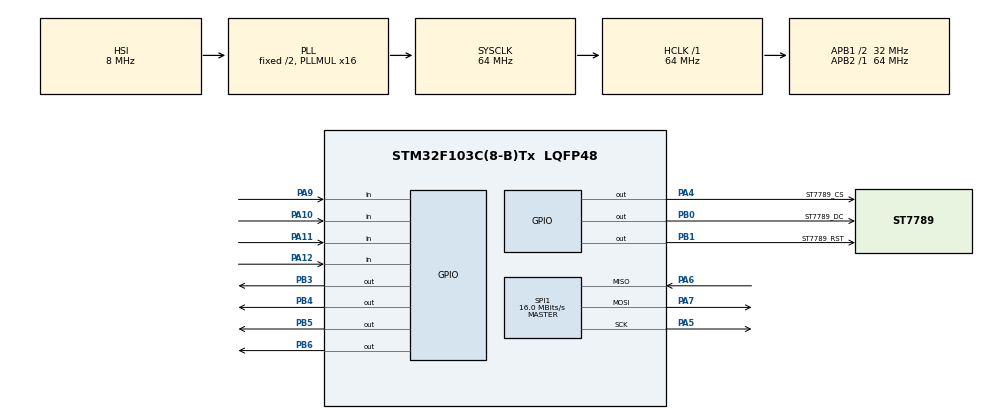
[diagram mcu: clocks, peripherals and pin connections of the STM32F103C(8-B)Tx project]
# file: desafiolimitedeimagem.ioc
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Mcu.Family=STM32F1
Mcu.Name=STM32F103C(8-B)Tx
Mcu.Package=LQFP48
NVIC.PriorityGroup=NVIC_PRIORITYGROUP_4
PA10.Signal=GPIO_Input
PA11.Signal=GPIO_Input
PA12.Signal=GPIO_Input
PA13.Mode=Serial_Wire
PA13.Signal=SYS_JTMS-SWDIO
PA14.Mode=Serial_Wire
PA14.Signal=SYS_JTCK-SWCLK
PA4.GPIO_Label=ST7789_CS
PA4.Signal=GPIO_Output
PA5.Mode=Full_Duplex_Master
PA5.Signal=SPI1_SCK
PA6.Mode=Full_Duplex_Master
PA6.Signal=SPI1_MISO
PA7.Mode=Full_Duplex_Master
PA7.Signal=SPI1_MOSI
PA9.Signal=GPIO_Input
PB0.GPIO_Label=ST7789_DC
PB0.Signal=GPIO_Output
PB1.GPIO_Label=ST7789_RST
PB1.Signal=GPIO_Output
PB3.Signal=GPIO_Output
PB4.Signal=GPIO_Output
PB5.Signal=GPIO_Output
PB6.Signal=GPIO_Output
ProjectManager.HeapSize=0x200
ProjectManager.StackSize=0x400
ProjectManager.TargetToolchain=STM32CubeIDE
RCC.AHBFreq_Value=64000000
RCC.APB1CLKDivider=RCC_HCLK_DIV2
RCC.APB1Freq_Value=32000000
RCC.APB1TimFreq_Value=64000000
RCC.APB2Freq_Value=64000000
RCC.APB2TimFreq_Value=64000000
RCC.HCLKFreq_Value=64000000
RCC.PLLMUL=RCC_PLL_MUL16
RCC.SYSCLKFreq_VALUE=64000000
RCC.SYSCLKSource=RCC_SYSCLKSOURCE_PLLCLK
RCC.USBFreq_Value=64000000
SPI1.BaudRatePrescaler=SPI_BAUDRATEPRESCALER_4
SPI1.CLKPolarity=SPI_POLARITY_HIGH
SPI1.CalculateBaudRate=16.0 MBits/s
SPI1.Direction=SPI_DIRECTION_2LINES
SPI1.Mode=SPI_MODE_MASTER
SPI1.VirtualType=VM_MASTER
board=custom

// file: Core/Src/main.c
/* USER CODE BEGIN Header */
/**
  ******************************************************************************
  * @file           : main.c
  * @brief          : Main program body
  ******************************************************************************
  * @attention
  *
  * <h2><center>&copy; Copyright (c) 2025 STMicroelectronics.
  * All rights reserved.</center></h2>
  *
  * This software component is licensed by ST under BSD 3-Clause license,
  * the "License"; You may not use this file except in compliance with the
  * License. You may obtain a copy of the License at:
  *                        opensource.org/licenses/BSD-3-Clause
  *
  ******************************************************************************
  */
/* USER CODE END Header */
#include "main.h"
#include "ST7789\ST7789.h"

SPI_HandleTypeDef hspi1;

/* USER CODE BEGIN PV */

#define IMG0_HEIGHT 60
#define IMG0_WIDTH 60

// array size is 7200
static const uint16_t img0[][60*60/2]  = {
  0xffff, 0xffff, 0xffff, 0xffff, 0xffff, 0xffff, 0xffff, 0xffff, 0xffff, 0xffff, 0xffff, 0xffff, 0xffff, 0xffff, 0xffff, 0xffff, 0xffff, 0xffff, 0xffff, 0xffff, 0xffff, 0xffff, 0xffff, 0xffff, 0xffff, 0xffff, 0xffff, 0xffff, 0xffff, 0xffff, 0xffff, 0xffff, 0xffff, 0xffff, 0xffff, 0xffff, 0xffff, 0xffff, 0xffff, 0xffff, 0xffff, 0xffff, 0xffff, 0xffff, 0xffff, 0xffff, 0xffff, 0xffff, 0xffff, 0xffff, 0xffff, 0xffff, 0xffff, 0xffff, 0xffff, 0xffff, 0xffff, 0xffff, 0xffff, 0xffff,
  0xffff, 0xffff, 0xffff, 0xffff, 0xffff, 0xffff, 0xffff, 0xffff, 0xffff, 0xffff, 0xffff, 0xffff, 0xffff, 0xffff, 0xffff, 0xffff, 0xffff, 0xffff, 0xffff, 0xffff, 0xffff, 0xffff, 0xffff, 0xffff, 0xffff, 0xffff, 0xffff, 0xffff, 0xffff, 0xffff, 0xffff, 0xffff, 0xffff, 0xffff, 0xffff, 0xffff, 0xffff, 0xffff, 0xffff, 0xffff, 0xffff, 0xffff, 0xffff, 0xffff, 0xffff, 0xffff, 0xffff, 0xffff, 0xffff, 0xffff, 0xffff, 0xffff, 0xffff, 0xffff, 0xffff, 0xffff, 0xffff, 0xffff, 0xffff, 0xffff,
  0xffff, 0xffff, 0xffff, 0xffff, 0xffff, 0xffff, 0xffff, 0xffff, 0xffff, 0xffff, 0xffff, 0xffff, 0xffff, 0xffff, 0xffff, 0xffff, 0xffff, 0xffff, 0xffff, 0xffff, 0xffff, 0xffff, 0xffff, 0xffff, 0xffff, 0xffff, 0xffff, 0xffff, 0xffff, 0xffff, 0xffff, 0xffff, 0xffff, 0xffff, 0xffff, 0xffff, 0xffff, 0xffff, 0xffff, 0xffff, 0xffff, 0xffff, 0xffff, 0xffff, 0xffff, 0xffff, 0xffff, 0xffff, 0xffff, 0xffff, 0xffff, 0xffff, 0xffff, 0xffff, 0xffff, 0xffff, 0xffff, 0xffff, 0xffff, 0xffff,
  0xffff, 0xffff, 0xffff, 0xffff, 0xffff, 0xffff, 0xffff, 0xffff, 0xffff, 0xffff, 0xffff, 0xffff, 0xffff, 0xffff, 0xffff, 0xffff, 0xffff, 0xffff, 0xffff, 0xffff, 0xffff, 0xffff, 0xffff, 0xffff, 0xffff, 0xffff, 0xffff, 0xffff, 0xffff, 0xffff, 0xffff, 0xffff, 0xffff, 0xffff, 0xffff, 0xffff, 0xffff, 0xffff, 0xffff, 0xffff, 0xffff, 0xffff, 0xffff, 0xffff, 0xffff, 0xffff, 0xffff, 0xffff, 0xffff, 0xffff, 0xffff, 0xffff, 0xffff, 0xffff, 0xffff, 0xffff, 0xffff, 0xffff, 0xffff, 0xffff,
  0xffff, 0xffff, 0xffff, 0xffff, 0xffff, 0xffff, 0xffff, 0xffff, 0xffff, 0xffff, 0xffff, 0xffff, 0xffff, 0xffff, 0xffff, 0xffff, 0xffff, 0xffff, 0xffff, 0xffff, 0xffff, 0xffff, 0xffff, 0xffff, 0xffff, 0xffff, 0xffff, 0xffff, 0xffff, 0xffff, 0xffff, 0xffff, 0xffff, 0xffff, 0xffff, 0xffff, 0xffff, 0xffff, 0xffff, 0xffff, 0xffff, 0xffff, 0xffff, 0xffff, 0xffff, 0xffff, 0xffff, 0xffff, 0xffff, 0xffff, 0xffff, 0xffff, 0xffff, 0xffff, 0xffff, 0xffff, 0xffff, 0xffff, 0xffff, 0xffff,
  0xffff, 0xffff, 0xffff, 0xffff, 0xffff, 0xffff, 0xffff, 0xffff, 0xffff, 0xffff, 0xffff, 0xffff, 0xffff, 0xffff, 0xffff, 0xffff, 0xffff, 0xffff, 0xffff, 0xffff, 0xffff, 0xffff, 0xffff, 0xffff, 0xffff, 0xffff, 0xffff, 0xffff, 0xffff, 0xffff, 0xffff, 0xffff, 0xffff, 0xffff, 0xffff, 0xffff, 0xffff, 0xffff, 0xffff, 0xffff, 0xffff, 0xffff, 0xffff, 0xffff, 0xffff, 0xffff, 0xffff, 0xffff, 0xffff, 0xffff, 0xffff, 0xffff, 0xffff, 0xffff, 0xffff, 0xffff, 0xffff, 0xffff, 0xffff, 0xffff,
  0xffff, 0xffff, 0xffff, 0xffff, 0xffff, 0xffff, 0xffff, 0xffff, 0xffff, 0xffff, 0xffff, 0xffff, 0xffff, 0xffff, 0xffff, 0xffff, 0xffff, 0xffff, 0xffff, 0xffff, 0xffff, 0xffff, 0xffff, 0xffff, 0xffff, 0xffff, 0xffff, 0xffff, 0xffff, 0xffff, 0xffff, 0xffff, 0xffff, 0xffff, 0xffff, 0xffff, 0xffff, 0xffff, 0xffff, 0xffff, 0xffff, 0xffff, 0xffff, 0xffff, 0xffff, 0xffff, 0xffff, 0xffff, 0xffff, 0xffff, 0xffff, 0xffff, 0xffff, 0xffff, 0xffff, 0xffff, 0xffff, 0xffff, 0xffff, 0xffff,
  0xffff, 0xffff, 0xffff, 0xffff, 0xffff, 0xffff, 0xffff, 0xffff, 0xffff, 0xffff, 0xffff, 0xffff, 0xffff, 0xffff, 0xffff, 0xffff, 0xffff, 0xffff, 0xffff, 0xffff, 0xffff, 0xffff, 0xffff, 0xffff, 0xffff, 0xffff, 0xffff, 0xffff, 0xffff, 0xffff, 0xffff, 0xffff, 0xffff, 0xffff, 0xffff, 0xffff, 0xffff, 0xffff, 0xffff, 0xffff, 0xffff, 0xffff, 0xffff, 0xffff, 0xffff, 0xffff, 0xffff, 0xffff, 0xffff, 0xffff, 0xffff, 0xffff, 0xffff, 0xffff, 0xffff, 0xffff, 0xffff, 0xffff, 0xffff, 0xffff,
  0xffff, 0xffff, 0xffff, 0xffff, 0xffff, 0xffff, 0xffff, 0xffff, 0xffff, 0xffff, 0xffff, 0xffff, 0xffff, 0xffff, 0xffff, 0xffff, 0xffff, 0xffff, 0xffff, 0xffff, 0xffff, 0xffff, 0xffff, 0xffff, 0xffff, 0xffff, 0xffff, 0xffff, 0xffff, 0xffff, 0xffff, 0xffff, 0xffff, 0xffff, 0xffff, 0xffff, 0xffff, 0xffff, 0xffff, 0xffff, 0xffff, 0xffff, 0xffff, 0xffff, 0xffff, 0xffff, 0xffff, 0xffff, 0xffff, 0xffff, 0xffff, 0xffff, 0xffff, 0xffff, 0xffff, 0xffff, 0xffff, 0xffff, 0xffff, 0xffff,
  0xffff, 0xffff, 0xffff, 0xffff, 0xffff, 0xffff, 0xffff, 0xffff, 0xffff, 0xffff, 0xffff, 0xffff, 0xffff, 0xffff, 0xffff, 0xffff, 0xffff, 0xffff, 0xffff, 0xffff, 0xffff, 0xffff, 0xffff, 0xffff, 0xffff, 0xffff, 0xffff, 0xffff, 0xffff, 0xffff, 0xffff, 0xffff, 0xffff, 0xffff, 0xffff, 0xffff, 0xffff, 0xffff, 0xffff, 0xffff, 0xffff, 0xffff, 0xffff, 0xffff, 0xffff, 0xffff, 0xffff, 0xffff, 0xffff, 0xffff, 0xffff, 0xffff, 0xffff, 0xffff, 0xffff, 0xffff, 0xffff, 0xffff, 0xffff, 0xffff,
  0xffff, 0xffff, 0xffff, 0xffff, 0xffff, 0xffff, 0xffff, 0xffff, 0xffff, 0xffff, 0xffff, 0xffff, 0xffff, 0xffff, 0xffff, 0xffff, 0xffff, 0xffff, 0xffff, 0xffff, 0xffff, 0xffff, 0xffff, 0xffff, 0xffff, 0xffff, 0xffff, 0xffff, 0xffff, 0xffff, 0xffff, 0xffff, 0xffff, 0xffff, 0xffff, 0xffff, 0xffff, 0xffff, 0xffff, 0xffff, 0xffff, 0xffff, 0xffff, 0xffff, 0xffff, 0xffff, 0xffff, 0xffff, 0xffff, 0xffff, 0xffff, 0xffff, 0xffff, 0xffff, 0xffff, 0xffff, 0xffff, 0xffff, 0xffff, 0xffff,
  0xffff, 0xffff, 0xffff, 0xffff, 0xffff, 0xffff, 0xffff, 0xffff, 0xffff, 0xffff, 0xffff, 0xffff, 0xffff, 0xffff, 0xffff, 0xffff, 0xffff, 0xffff, 0xffff, 0xffff, 0xffff, 0xffff, 0xffff, 0xffff, 0xffff, 0xffff, 0xffff, 0xffff, 0xffff, 0xffff, 0xffff, 0xffff, 0xffff, 0xffff, 0xffff, 0xffff, 0xffff, 0xffff, 0xffff, 0xffff, 0xffff, 0xffff, 0xffff, 0xffff, 0xffff, 0xffff, 0xffff, 0xffff, 0xffff, 0xffff, 0xffff, 0xffff, 0xffff, 0xffff, 0xffff, 0xffff, 0xffff, 0xffff, 0xffff, 0xffff,
  0xffff, 0xffff, 0xffff, 0xffff, 0xffff, 0xffff, 0xffff, 0xffff, 0xffff, 0xffff, 0xffff, 0xffff, 0xffff, 0xffff, 0xffff, 0xffff, 0xffff, 0xffff, 0xffff, 0xffff, 0xffff, 0xffff, 0xffff, 0xffff, 0xffff, 0xffff, 0xffff, 0xffff, 0xffff, 0xffff, 0xffff, 0xffff, 0xffff, 0xffff, 0xffff, 0xffff, 0xffff, 0xffff, 0xffff, 0xffff, 0xffff, 0xffff, 0xffff, 0xffff, 0xffff, 0xffff, 0xffff, 0xffff, 0xffff, 0xffff, 0xffff, 0xffff, 0xffff, 0xffff, 0xffff, 0xffff, 0xffff, 0xffff, 0xffff, 0xffff,
  0xffff, 0xffff, 0xffff, 0xffff, 0xffff, 0xffff, 0xffff, 0xffff, 0xffff, 0xffff, 0xffff, 0xffff, 0xffff, 0xffff, 0xffff, 0xffff, 0xffff, 0xffff, 0xffff, 0xffff, 0xffff, 0xffff, 0xffff, 0xffff, 0xffff, 0xffff, 0xffff, 0xffff, 0xffff, 0xffff, 0xffff, 0xffff, 0xffff, 0xffff, 0xffff, 0xffff, 0xffff, 0xffff, 0xffff, 0xffff, 0xffff, 0xffff, 0xffff, 0xffff, 0xffff, 0xffff, 0xffff, 0xffff, 0xffff, 0xffff, 0xffff, 0xffff, 0xffff, 0xffff, 0xffff, 0xffff, 0xffff, 0xffff, 0xffff, 0xffff,
  0xffff, 0xffff, 0xffff, 0xffff, 0xffff, 0xffff, 0xffff, 0xffff, 0xffff, 0xffff, 0xffff, 0xffff, 0xffff, 0xffff, 0xffff, 0xffff, 0xffff, 0xffff, 0xffff, 0xffff, 0xffff, 0xffff, 0xffff, 0xffff, 0xffff, 0xffff, 0xffff, 0xffff, 0xffff, 0xffff, 0xffff, 0xffff, 0xffff, 0xffff, 0xffff, 0xffff, 0xffff, 0xffff, 0xffff, 0xffff, 0xffff, 0xffff, 0xffff, 0xffff, 0xffff, 0xffff, 0xffff, 0xffff, 0xffff, 0xffff, 0xffff, 0xffff, 0xffff, 0xffff, 0xffff, 0xffff, 0xffff, 0xffff, 0xffff, 0xffff,
  0xffff, 0xffff, 0xffff, 0xffff, 0xffff, 0xffff, 0xffff, 0xffff, 0xffff, 0xffff, 0xffff, 0xffff, 0xffff, 0xffff, 0xffff, 0xffff, 0xffff, 0xffff, 0xffff, 0xffff, 0xffff, 0xffff, 0xffff, 0xffff, 0xffff, 0xffff, 0xffff, 0xffff, 0xffff, 0xffff, 0xffff, 0xffff, 0xffff, 0xffff, 0xffff, 0xffff, 0xffff, 0xffff, 0xffff, 0xffff, 0xffff, 0xffff, 0xffff, 0xffff, 0xffff, 0xffff, 0xffff, 0xffff, 0xffff, 0xffff, 0xffff, 0xffff, 0xffff, 0xffff, 0xffff, 0xffff, 0xffff, 0xffff, 0xffff, 0xffff,
  0xffff, 0xffff, 0xffff, 0xffff, 0xffff, 0xffff, 0xffff, 0xffff, 0xffff, 0xffff, 0xffff, 0xffff, 0xffff, 0xffff, 0xffff, 0xffff, 0xffff, 0xffff, 0xffff, 0xffff, 0xffff, 0xffff, 0xffff, 0xffff, 0xffff, 0xffff, 0xdef7, 0xbdef, 0x7bd7, 0x5ac7, 0x59c7, 0x59c7, 0x59c7, 0x7bcf, 0xbde7, 0xdeef, 0xfff7, 0xffff, 0xffff, 0xffff, 0xffff, 0xffff, 0xffff, 0xffff, 0xffff, 0xffff, 0xffff, 0xffff, 0xffff, 0xffff, 0xffff, 0xffff, 0xffff, 0xffff, 0xffff, 0xffff, 0xffff, 0xffff, 0xffff, 0xffff,
  0xffff, 0xffff, 0xffff, 0xffff, 0xffff, 0xffff, 0xffff, 0xffff, 0xffff, 0xffff, 0xffff, 0xffff, 0xffff, 0xffff, 0xffff, 0xffff, 0xffff, 0xffff, 0xffff, 0xffff, 0xffff, 0xffff, 0xffff, 0xffff, 0xffff, 0xffff, 0xbce7, 0x59bf, 0x7176, 0xed4d, 0xed4d, 0xed4d, 0xed4d, 0x516e, 0x17af, 0x7acf, 0xbde7, 0xdef7, 0xffff, 0xffff, 0xffff, 0xffff, 0xffff, 0xffff, 0xffff, 0xffff, 0xffff, 0xffff, 0xffff, 0xffff, 0xffff, 0xffff, 0xffff, 0xffff, 0xffff, 0xffff, 0xffff, 0xffff, 0xffff, 0xffff,
  0xffff, 0xffff, 0xffff, 0xffff, 0xffff, 0xffff, 0xffff, 0xffff, 0xffff, 0xffff, 0xffff, 0xffff, 0xffff, 0xffff, 0xffff, 0xffff, 0xffff, 0xffff, 0xffff, 0xffff, 0xffff, 0xffff, 0xffff, 0xffff, 0xdef7, 0xbde7, 0x38b7, 0x9386, 0xed45, 0x8925, 0x8925, 0x8925, 0x8925, 0xcc3d, 0x7176, 0xd59e, 0x5ac7, 0xbde7, 0xffff, 0xffff, 0xffff, 0xffff, 0xffff, 0xffff, 0xffff, 0xffff, 0xffff, 0xffff, 0xffff, 0xffff, 0xffff, 0xffff, 0xffff, 0xffff, 0xffff, 0xffff, 0xffff, 0xffff, 0xffff, 0xffff,
  0xffff, 0xffff, 0xffff, 0xffff, 0xffff, 0xffff, 0xffff, 0xffff, 0xffff, 0xffff, 0xffff, 0xffff, 0xffff, 0xffff, 0xffff, 0xffff, 0xffff, 0xffff, 0xffff, 0xffff, 0xffff, 0xffff, 0xffff, 0xffff, 0xbce7, 0x59c7, 0x516e, 0xab35, 0x8a2d, 0x8925, 0x8925, 0x8925, 0x8925, 0x8a25, 0xaa35, 0x2f5e, 0xd59e, 0x7bcf, 0xffff, 0xffff, 0xffff, 0xffff, 0xffff, 0xffff, 0xffff, 0xffff, 0xffff, 0xffff, 0xffff, 0xffff, 0xffff, 0xffff, 0xffff, 0xffff, 0xffff, 0xffff, 0xffff, 0xffff, 0xffff, 0xffff,
  0xffff, 0xffff, 0xffff, 0xffff, 0xffff, 0xffff, 0xffff, 0xffff, 0xffff, 0xffff, 0xffff, 0xffff, 0xffff, 0xffff, 0xffff, 0xffff, 0xffff, 0xffff, 0xffff, 0xffff, 0xffff, 0xffff, 0xffff, 0xffff, 0x39bf, 0x9386, 0xed45, 0x8925, 0x8925, 0x8925, 0x8925, 0x8925, 0x8925, 0x8925, 0x8925, 0xcc3d, 0x5066, 0x38b7, 0xffff, 0xffff, 0xffff, 0xffff, 0xffff, 0xffff, 0xffff, 0xffff, 0xffff, 0xffff, 0xffff, 0xffff, 0xffff, 0xffff, 0xffff, 0xffff, 0xffff, 0xffff, 0xffff, 0xffff, 0xffff, 0xffff,
  0xffff, 0xffff, 0xffff, 0xffff, 0xffff, 0xffff, 0xffff, 0xffff, 0xffff, 0xffff, 0xffff, 0xffff, 0xffff, 0xffff, 0xffff, 0xffff, 0xffff, 0xffff, 0xffff, 0xffff, 0xffff, 0xffff, 0xffff, 0xffff, 0xb386, 0xaa2d, 0x8925, 0x8925, 0x8925, 0x8925, 0x8925, 0x8925, 0x8925, 0x8925, 0x8925, 0x8925, 0x8a2d, 0xd596, 0xffff, 0xffff, 0xffff, 0xffff, 0xffff, 0xffff, 0xffff, 0xffff, 0xffff, 0xffff, 0xffff, 0xffff, 0xffff, 0xffff, 0xffff, 0xffff, 0xffff, 0xffff, 0xffff, 0xffff, 0xffff, 0xffff,
  0xffff, 0xffff, 0xffff, 0xffff, 0xffff, 0xffff, 0xffff, 0xffff, 0xffff, 0xffff, 0xffff, 0xffff, 0xffff, 0xffff, 0xffff, 0xffff, 0xffff, 0xffff, 0xffff, 0xffff, 0xffff, 0xffff, 0xffff, 0xffff, 0x9386, 0x8925, 0x8925, 0x8925, 0x8925, 0x8925, 0x8925, 0x8925, 0x8925, 0x8925, 0x8925, 0x8925, 0x8925, 0xd496, 0xffff, 0xffff, 0xffff, 0xffff, 0xffff, 0xffff, 0xffff, 0xffff, 0xffff, 0xffff, 0xffff, 0xffff, 0xffff, 0xffff, 0xffff, 0xffff, 0xffff, 0xffff, 0xffff, 0xffff, 0xffff, 0xffff,
  0xffff, 0xffff, 0xffff, 0xffff, 0xffff, 0xffff, 0xffff, 0xffff, 0xffff, 0xffff, 0xffff, 0xffff, 0xffff, 0xffff, 0xffff, 0xffff, 0xffff, 0xffff, 0xffff, 0xffff, 0xffff, 0xffff, 0xffff, 0xffff, 0x937e, 0x8925, 0x8925, 0x8925, 0x8925, 0x8925, 0x8925, 0x8925, 0x8925, 0x8925, 0x8925, 0x8925, 0x8925, 0xd496, 0xffff, 0xffff, 0xffff, 0xffff, 0xffff, 0xffff, 0xffff, 0xffff, 0xffff, 0xffff, 0xffff, 0xffff, 0xffff, 0xffff, 0xffff, 0xffff, 0xffff, 0xffff, 0xffff, 0xffff, 0xffff, 0xffff,
  0xffff, 0xffff, 0xffff, 0xffff, 0xffff, 0xffff, 0xffff, 0xffff, 0xffff, 0xffff, 0xffff, 0xffff, 0xffff, 0xffff, 0xffff, 0xffff, 0xffff, 0xffff, 0xffff, 0xffff, 0xffff, 0xffff, 0xffff, 0xffff, 0x9386, 0x8925, 0x8925, 0x8925, 0x8925, 0x8925, 0x8925, 0x8925, 0x8925, 0x8925, 0x8925, 0x8925, 0x8925, 0xd496, 0xffff, 0xffff, 0xffff, 0xffff, 0xffff, 0xffff, 0xffff, 0xffff, 0xffff, 0xffff, 0xffff, 0xffff, 0xffff, 0xffff, 0xffff, 0xffff, 0xffff, 0xffff, 0xffff, 0xffff, 0xffff, 0xffff,
  0xffff, 0xffff, 0xffff, 0xffff, 0xffff, 0xffff, 0xffff, 0xffff, 0xffff, 0xffff, 0xffff, 0xffff, 0xffff, 0xffff, 0xffff, 0xffff, 0xffff, 0xffff, 0xffff, 0xffff, 0xffff, 0xffff, 0xffff, 0xffff, 0x9386, 0x8a2d, 0x8925, 0x8925, 0x8925, 0x8925, 0x8925, 0x8925, 0x8925, 0x8925, 0x8925, 0x8925, 0x8925, 0xd496, 0xffff, 0xffff, 0xffff, 0xffff, 0xffff, 0xffff, 0xffff, 0xffff, 0xffff, 0xffff, 0xffff, 0xffff, 0xffff, 0xffff, 0xffff, 0xffff, 0xffff, 0xffff, 0xffff, 0xffff, 0xffff, 0xffff,
  0xffff, 0xffff, 0xffff, 0xffff, 0xffff, 0xffff, 0xffff, 0xffff, 0xffff, 0xffff, 0xffff, 0xffff, 0xffff, 0xffff, 0xffff, 0xffff, 0xffff, 0xffff, 0xffff, 0xffff, 0xffff, 0xffff, 0xffff, 0xffff, 0x17b7, 0x516e, 0xcc45, 0x8925, 0x8925, 0x8925, 0x8925, 0x8925, 0x8925, 0x8925, 0x8925, 0x8925, 0x8925, 0xd496, 0xffff, 0xffff, 0xffff, 0xffff, 0xffff, 0xffff, 0xffff, 0xffff, 0xffff, 0xffff, 0xffff, 0xffff, 0xffff, 0xffff, 0xffff, 0xffff, 0xffff, 0xffff, 0xffff, 0xffff, 0xffff, 0xffff,
  0xffff, 0xffff, 0xffff, 0xffff, 0xffff, 0xffff, 0xffff, 0xffff, 0xffff, 0xffff, 0xffff, 0xffff, 0xffff, 0xffff, 0xffff, 0xffff, 0xffff, 0xffff, 0xffff, 0xffff, 0xffff, 0xffff, 0xffff, 0xffff, 0x7bd7, 0xf6a6, 0x2f5e, 0xaa2d, 0x8925, 0x8925, 0x8925, 0x8925, 0x8925, 0x8925, 0x8925, 0x8a2d, 0xab35, 0xd59e, 0xffff, 0xffff, 0xffff, 0xffff, 0xffff, 0xffff, 0xffff, 0xffff, 0xffff, 0xffff, 0xffff, 0xffff, 0xffff, 0xffff, 0xffff, 0xffff, 0xffff, 0xffff, 0xffff, 0xffff, 0xffff, 0xffff,
  0xffff, 0xffff, 0xffff, 0xffff, 0xffff, 0xffff, 0xffff, 0xffff, 0xffff, 0xffff, 0xffff, 0xffff, 0xffff, 0xffff, 0xffff, 0xffff, 0xffff, 0xffff, 0xffff, 0xffff, 0xffff, 0xffff, 0xffff, 0xffff, 0xbde7, 0x7acf, 0xd596, 0x506e, 0xcc3d, 0x8925, 0x8925, 0x8925, 0x8925, 0x8925, 0x8925, 0xed4d, 0x9386, 0x5ac7, 0xffff, 0xffff, 0xffff, 0xffff, 0xffff, 0xffff, 0xffff, 0xffff, 0xffff, 0xffff, 0xffff, 0xffff, 0xffff, 0xffff, 0xffff, 0xffff, 0xffff, 0xffff, 0xffff, 0xffff, 0xffff, 0xffff,
  0xffff, 0xffff, 0xffff, 0xffff, 0xffff, 0xffff, 0xffff, 0xffff, 0xffff, 0xffff, 0xffff, 0xffff, 0xffff, 0xffff, 0xffff, 0xffff, 0xffff, 0xffff, 0xffff, 0xffff, 0xffff, 0xffff, 0xffff, 0xffff, 0xdef7, 0xbde7, 0x59c7, 0xf69e, 0x506e, 0xed4d, 0xed4d, 0xed4d, 0xed4d, 0xed4d, 0xed4d, 0x927e, 0x59c7, 0xbde7, 0xffff, 0xffff, 0xffff, 0xffff, 0xffff, 0xffff, 0xffff, 0xffff, 0xffff, 0xffff, 0xffff, 0xffff, 0xffff, 0xffff, 0xffff, 0xffff, 0xffff, 0xffff, 0xffff, 0xffff, 0xffff, 0xffff,
  0xffff, 0xffff, 0xffff, 0xffff, 0xffff, 0xffff, 0xffff, 0xffff, 0xffff, 0xffff, 0xffff, 0xffff, 0xffff, 0xffff, 0xffff, 0xffff, 0xffff, 0xffff, 0xffff, 0xffff, 0xffff, 0xffff, 0xffff, 0xffff, 0xffff, 0xfff7, 0xddef, 0xbce7, 0x7bd7, 0x5ac7, 0x5ac7, 0x5ac7, 0x5ac7, 0x5ac7, 0x5ac7, 0x9bd7, 0xddef, 0xfff7, 0xffff, 0xffff, 0xffff, 0xffff, 0xffff, 0xffff, 0xffff, 0xffff, 0xffff, 0xffff, 0xffff, 0xffff, 0xffff, 0xffff, 0xffff, 0xffff, 0xffff, 0xffff, 0xffff, 0xffff, 0xffff, 0xffff,
  0xffff, 0xffff, 0xffff, 0xffff, 0xffff, 0xffff, 0xffff, 0xffff, 0xffff, 0xffff, 0xffff, 0xffff, 0xffff, 0xffff, 0xffff, 0xffff, 0xffff, 0xffff, 0xffff, 0xffff, 0xffff, 0xffff, 0xffff, 0xffff, 0xffff, 0xffff, 0xffff, 0xffff, 0xffff, 0xffff, 0xffff, 0xffff, 0xffff, 0xffff, 0xffff, 0xffff, 0xffff, 0xffff, 0xffff, 0xffff, 0xffff, 0xffff, 0xffff, 0xffff, 0xffff, 0xffff, 0xffff, 0xffff, 0xffff, 0xffff, 0xffff, 0xffff, 0xffff, 0xffff, 0xffff, 0xffff, 0xffff, 0xffff, 0xffff, 0xffff,
  0xffff, 0xffff, 0xffff, 0xffff, 0xffff, 0xffff, 0xffff, 0xffff, 0xffff, 0xffff, 0xffff, 0xffff, 0xffff, 0xffff, 0xffff, 0xffff, 0xffff, 0xffff, 0xffff, 0xffff, 0xffff, 0xffff, 0xffff, 0xffff, 0xffff, 0xffff, 0xffff, 0xffff, 0xffff, 0xffff, 0xffff, 0xffff, 0xffff, 0xffff, 0xffff, 0xffff, 0xffff, 0xffff, 0xffff, 0xffff, 0xffff, 0xffff, 0xffff, 0xffff, 0xffff, 0xffff, 0xffff, 0xffff, 0xffff, 0xffff, 0xffff, 0xffff, 0xffff, 0xffff, 0xffff, 0xffff, 0xffff, 0xffff, 0xffff, 0xffff,
  0xffff, 0xffff, 0xffff, 0xffff, 0xffff, 0xffff, 0xffff, 0xffff, 0xffff, 0xffff, 0xffff, 0xffff, 0xffff, 0xffff, 0xffff, 0xffff, 0xffff, 0xffff, 0xffff, 0xffff, 0xffff, 0xffff, 0xffff, 0xffff, 0xffff, 0xffff, 0xffff, 0xffff, 0xffff, 0xffff, 0xffff, 0xffff, 0xffff, 0xffff, 0xffff, 0xffff, 0xffff, 0xffff, 0xffff, 0xffff, 0xffff, 0xffff, 0xffff, 0xffff, 0xffff, 0xffff, 0xffff, 0xffff, 0xffff, 0xffff, 0xffff, 0xffff, 0xffff, 0xffff, 0xffff, 0xffff, 0xffff, 0xffff, 0xffff, 0xffff,
  0xffff, 0xffff, 0xffff, 0xffff, 0xffff, 0xffff, 0xffff, 0xffff, 0xffff, 0xffff, 0xffff, 0xffff, 0xffff, 0xffff, 0xffff, 0xffff, 0xffff, 0xffff, 0xffff, 0xffff, 0xffff, 0xffff, 0xffff, 0xffff, 0xffff, 0xffff, 0xffff, 0xffff, 0xffff, 0xffff, 0xffff, 0xffff, 0xffff, 0xffff, 0xffff, 0xffff, 0xffff, 0xffff, 0xffff, 0xffff, 0xffff, 0xffff, 0xffff, 0xffff, 0xffff, 0xffff, 0xffff, 0xffff, 0xffff, 0xffff, 0xffff, 0xffff, 0xffff, 0xffff, 0xffff, 0xffff, 0xffff, 0xffff, 0xffff, 0xffff,
  0xffff, 0xffff, 0xffff, 0xffff, 0xffff, 0xffff, 0xffff, 0xffff, 0xffff, 0xffff, 0xffff, 0xffff, 0xffff, 0xffff, 0xffff, 0xffff, 0xffff, 0xffff, 0xffff, 0xffff, 0xffff, 0xffff, 0xffff, 0xffff, 0xffff, 0xffff, 0xffff, 0xffff, 0xffff, 0xffff, 0xffff, 0xffff, 0xffff, 0xffff, 0xffff, 0xffff, 0xffff, 0xffff, 0xffff, 0xffff, 0xffff, 0xffff, 0xffff, 0xffff, 0xffff, 0xffff, 0xffff, 0xffff, 0xffff, 0xffff, 0xffff, 0xffff, 0xffff, 0xffff, 0xffff, 0xffff, 0xffff, 0xffff, 0xffff, 0xffff,
  0xffff, 0xffff, 0xffff, 0xffff, 0xffff, 0xffff, 0xffff, 0xffff, 0xffff, 0xffff, 0xffff, 0xffff, 0xffff, 0xffff, 0xffff, 0xffff, 0xffff, 0xffff, 0xffff, 0xffff, 0xffff, 0xffff, 0xffff, 0xffff, 0xffff, 0xffff, 0xffff, 0xffff, 0xffff, 0xffff, 0xffff, 0xffff, 0xffff, 0xffff, 0xffff, 0xffff, 0xffff, 0xffff, 0xffff, 0xffff, 0xffff, 0xffff, 0xffff, 0xffff, 0xffff, 0xffff, 0xffff, 0xffff, 0xffff, 0xffff, 0xffff, 0xffff, 0xffff, 0xffff, 0xffff, 0xffff, 0xffff, 0xffff, 0xffff, 0xffff,
  0xffff, 0xffff, 0xffff, 0xffff, 0xffff, 0xffff, 0xffff, 0xffff, 0xffff, 0xffff, 0xffff, 0xffff, 0xffff, 0xffff, 0xffff, 0xffff, 0xffff, 0xffff, 0xffff, 0xffff, 0xffff, 0xffff, 0xffff, 0xffff, 0xffff, 0xffff, 0xffff, 0xffff, 0xffff, 0xffff, 0xffff, 0xffff, 0xffff, 0xffff, 0xffff, 0xffff, 0xffff, 0xffff, 0xffff, 0xffff, 0xffff, 0xffff, 0xffff, 0xffff, 0xffff, 0xffff, 0xffff, 0xffff, 0xffff, 0xffff, 0xffff, 0xffff, 0xffff, 0xffff, 0xffff, 0xffff, 0xffff, 0xffff, 0xffff, 0xffff,
  0xffff, 0xffff, 0xffff, 0xffff, 0xffff, 0xffff, 0xffff, 0xffff, 0xffff, 0xffff, 0xffff, 0xffff, 0xffff, 0xffff, 0xffff, 0xffff, 0xffff, 0xffff, 0xffff, 0xffff, 0xffff, 0xffff, 0xffff, 0xffff, 0xffff, 0xffff, 0xffff, 0xffff, 0xffff, 0xffff, 0xffff, 0xffff, 0xffff, 0xffff, 0xffff, 0xffff, 0xffff, 0xffff, 0xffff, 0xffff, 0xffff, 0xffff, 0xffff, 0xffff, 0xffff, 0xffff, 0xffff, 0xffff, 0xffff, 0xffff, 0xffff, 0xffff, 0xffff, 0xffff, 0xffff, 0xffff, 0xffff, 0xffff, 0xffff, 0xffff,
  0xffff, 0xffff, 0xffff, 0xffff, 0xffff, 0xffff, 0xffff, 0xffff, 0xffff, 0xffff, 0xffff, 0xffff, 0xffff, 0xffff, 0xffff, 0xffff, 0xffff, 0xffff, 0xffff, 0xffff, 0xffff, 0xffff, 0xffff, 0xffff, 0xffff, 0xffff, 0xffff, 0xffff, 0xffff, 0xffff, 0xffff, 0xffff, 0xffff, 0xffff, 0xffff, 0xffff, 0xffff, 0xffff, 0xffff, 0xffff, 0xffff, 0xffff, 0xffff, 0xffff, 0xffff, 0xffff, 0xffff, 0xffff, 0xffff, 0xffff, 0xffff, 0xffff, 0xffff, 0xffff, 0xffff, 0xffff, 0xffff, 0xffff, 0xffff, 0xffff,
  0xffff, 0xffff, 0xffff, 0xffff, 0xffff, 0xffff, 0xffff, 0xffff, 0xffff, 0xffff, 0xffff, 0xffff, 0xffff, 0xffff, 0xffff, 0xffff, 0xffff, 0xffff, 0xffff, 0xffff, 0xffff, 0xffff, 0xffff, 0xffff, 0xffff, 0xffff, 0xffff, 0xffff, 0xffff, 0xffff, 0xffff, 0xffff, 0xffff, 0xffff, 0xffff, 0xffff, 0xffff, 0xffff, 0xffff, 0xffff, 0xffff, 0xffff, 0xffff, 0xffff, 0xffff, 0xffff, 0xffff, 0xffff, 0xffff, 0xffff, 0xffff, 0xffff, 0xffff, 0xffff, 0xffff, 0xffff, 0xffff, 0xffff, 0xffff, 0xffff,
  0xffff, 0xffff, 0xffff, 0xffff, 0xffff, 0xffff, 0xffff, 0xffff, 0xffff, 0xffff, 0xffff, 0xffff, 0xffff, 0xffff, 0xffff, 0xffff, 0xffff, 0xffff, 0xffff, 0xffff, 0xffff, 0xffff, 0xffff, 0xffff, 0xffff, 0xffff, 0xffff, 0xffff, 0xffff, 0xffff, 0xffff, 0xffff, 0xffff, 0xffff, 0xffff, 0xffff, 0xffff, 0xffff, 0xffff, 0xffff, 0xffff, 0xffff, 0xffff, 0xffff, 0xffff, 0xffff, 0xffff, 0xffff, 0xffff, 0xffff, 0xffff, 0xffff, 0xffff, 0xffff, 0xffff, 0xffff, 0xffff, 0xffff, 0xffff, 0xffff,
  0xffff, 0xffff, 0xffff, 0xffff, 0xffff, 0xffff, 0xffff, 0xffff, 0xffff, 0xffff, 0xffff, 0xffff, 0xffff, 0xffff, 0xffff, 0xffff, 0xffff, 0xffff, 0xffff, 0xffff, 0xffff, 0xffff, 0xffff, 0xffff, 0xffff, 0xffff, 0xffff, 0xffff, 0xffff, 0xffff, 0xffff, 0xffff, 0xffff, 0xffff, 0xffff, 0xffff, 0xffff, 0xffff, 0xffff, 0xffff, 0xffff, 0xffff, 0xffff, 0xffff, 0xffff, 0xffff, 0xffff, 0xffff, 0xffff, 0xffff, 0xffff, 0xffff, 0xffff, 0xffff, 0xffff, 0xffff, 0xffff, 0xffff, 0xffff, 0xffff,
  0xffff, 0xffff, 0xffff, 0xffff, 0xffff, 0xffff, 0xffff, 0xffff, 0xffff, 0xffff, 0xffff, 0xffff, 0xffff, 0xffff, 0xffff, 0xffff, 0xffff, 0xffff, 0xffff, 0xffff, 0xffff, 0xffff, 0xffff, 0xffff, 0xffff, 0xffff, 0xffff, 0xffff, 0xffff, 0xffff, 0xffff, 0xffff, 0xffff, 0xffff, 0xffff, 0xffff, 0xffff, 0xffff, 0xffff, 0xffff, 0xffff, 0xffff, 0xffff, 0xffff, 0xffff, 0xffff, 0xffff, 0xffff, 0xffff, 0xffff, 0xffff, 0xffff, 0xffff, 0xffff, 0xffff, 0xffff, 0xffff, 0xffff, 0xffff, 0xffff,
  0xffff, 0xffff, 0xffff, 0xffff, 0xffff, 0xffff, 0xffff, 0xffff, 0xffff, 0xffff, 0xffff, 0xffff, 0xffff, 0xffff, 0xffff, 0xffff, 0xffff, 0xffff, 0xffff, 0xffff, 0xffff, 0xffff, 0xffff, 0xffff, 0xffff, 0xffff, 0xffff, 0xffff, 0xffff, 0xffff, 0xffff, 0xffff, 0xffff, 0xffff, 0xffff, 0xffff, 0xffff, 0xffff, 0xffff, 0xffff, 0xffff, 0xffff, 0xffff, 0xffff, 0xffff, 0xffff, 0xffff, 0xffff, 0xffff, 0xffff, 0xffff, 0xffff, 0xffff, 0xffff, 0xffff, 0xffff, 0xffff, 0xffff, 0xffff, 0xffff,
  0xffff, 0xffff, 0xffff, 0xffff, 0xffff, 0xffff, 0xffff, 0xffff, 0xffff, 0xffff, 0xffff, 0xffff, 0xffff, 0xffff, 0xffff, 0xffff, 0xffff, 0xffff, 0xffff, 0xffff, 0xffff, 0xffff, 0xffff, 0xffff, 0xffff, 0xffff, 0xffff, 0xffff, 0xffff, 0xffff, 0xffff, 0xffff, 0xffff, 0xffff, 0xffff, 0xffff, 0xffff, 0xffff, 0xffff, 0xffff, 0xffff, 0xffff, 0xffff, 0xffff, 0xffff, 0xffff, 0xffff, 0xffff, 0xffff, 0xffff, 0xffff, 0xffff, 0xffff, 0xffff, 0xffff, 0xffff, 0xffff, 0xffff, 0xffff, 0xffff,
  0xffff, 0xffff, 0xffff, 0xffff, 0xffff, 0xffff, 0xffff, 0xffff, 0xffff, 0xffff, 0xffff, 0xffff, 0xffff, 0xffff, 0xffff, 0xffff, 0xffff, 0xffff, 0xffff, 0xffff, 0xffff, 0xffff, 0xffff, 0xffff, 0xffff, 0xffff, 0xffff, 0xffff, 0xffff, 0xffff, 0xffff, 0xffff, 0xffff, 0xffff, 0xffff, 0xffff, 0xffff, 0xffff, 0xffff, 0xffff, 0xffff, 0xffff, 0xffff, 0xffff, 0xffff, 0xffff, 0xffff, 0xffff, 0xffff, 0xffff, 0xffff, 0xffff, 0xffff, 0xffff, 0xffff, 0xffff, 0xffff, 0xffff, 0xffff, 0xffff,
  0xffff, 0xffff, 0xffff, 0xffff, 0xffff, 0xffff, 0xffff, 0xffff, 0xffff, 0xffff, 0xffff, 0xffff, 0xffff, 0xffff, 0xffff, 0xffff, 0xffff, 0xffff, 0xffff, 0xffff, 0xffff, 0xffff, 0xffff, 0xffff, 0xffff, 0xffff, 0xffff, 0xffff, 0xffff, 0xffff, 0xffff, 0xffff, 0xffff, 0xffff, 0xffff, 0xffff, 0xffff, 0xffff, 0xffff, 0xffff, 0xffff, 0xffff, 0xffff, 0xffff, 0xffff, 0xffff, 0xffff, 0xffff, 0xffff, 0xffff, 0xffff, 0xffff, 0xffff, 0xffff, 0xffff, 0xffff, 0xffff, 0xffff, 0xffff, 0xffff,
  0xffff, 0xffff, 0xffff, 0xffff, 0xffff, 0xffff, 0xffff, 0xffff, 0xffff, 0xffff, 0xffff, 0xffff, 0xffff, 0xffff, 0xffff, 0xffff, 0xffff, 0xffff, 0xffff, 0xffff, 0xffff, 0xffff, 0xffff, 0xffff, 0xffff, 0xffff, 0xffff, 0xffff, 0xffff, 0xffff, 0xffff, 0xffff, 0xffff, 0xffff, 0xffff, 0xffff, 0xffff, 0xffff, 0xffff, 0xffff, 0xffff, 0xffff, 0xffff, 0xffff, 0xffff, 0xffff, 0xffff, 0xffff, 0xffff, 0xffff, 0xffff, 0xffff, 0xffff, 0xffff, 0xffff, 0xffff, 0xffff, 0xffff, 0xffff, 0xffff,
  0xffff, 0xffff, 0xffff, 0xffff, 0xffff, 0xffff, 0xffff, 0xffff, 0xffff, 0xffff, 0xffff, 0xffff, 0xffff, 0xffff, 0xffff, 0xffff, 0xffff, 0xffff, 0xffff, 0xffff, 0xffff, 0xffff, 0xffff, 0xffff, 0xffff, 0xffff, 0xffff, 0xffff, 0xffff, 0xffff, 0xffff, 0xffff, 0xffff, 0xffff, 0xffff, 0xffff, 0xffff, 0xffff, 0xffff, 0xffff, 0xffff, 0xffff, 0xffff, 0xffff, 0xffff, 0xffff, 0xffff, 0xffff, 0xffff, 0xffff, 0xffff, 0xffff, 0xffff, 0xffff, 0xffff, 0xffff, 0xffff, 0xffff, 0xffff, 0xffff,
  0xffff, 0xffff, 0xffff, 0xffff, 0xffff, 0xffff, 0xffff, 0xffff, 0xffff, 0xffff, 0xffff, 0xffff, 0xffff, 0xffff, 0xffff, 0xffff, 0xffff, 0xffff, 0xffff, 0xffff, 0xffff, 0xffff, 0xffff, 0xffff, 0xffff, 0xffff, 0xffff, 0xffff, 0xffff, 0xffff, 0xffff, 0xffff, 0xffff, 0xffff, 0xffff, 0xffff, 0xffff, 0xffff, 0xffff, 0xffff, 0xffff, 0xffff, 0xffff, 0xffff, 0xffff, 0xffff, 0xffff, 0xffff, 0xffff, 0xffff, 0xffff, 0xffff, 0xffff, 0xffff, 0xffff, 0xffff, 0xffff, 0xffff, 0xffff, 0xffff,
  0xffff, 0xffff, 0xffff, 0xffff, 0xffff, 0xffff, 0xffff, 0xffff, 0xffff, 0xffff, 0xffff, 0xffff, 0xffff, 0xffff, 0xffff, 0xffff, 0xffff, 0xffff, 0xffff, 0xffff, 0xffff, 0xffff, 0xffff, 0xffff, 0xffff, 0xffff, 0xffff, 0xffff, 0xffff, 0xffff, 0xffff, 0xffff, 0xffff, 0xffff, 0xffff, 0xffff, 0xffff, 0xffff, 0xffff, 0xffff, 0xffff, 0xffff, 0xffff, 0xffff, 0xffff, 0xffff, 0xffff, 0xffff, 0xffff, 0xffff, 0xffff, 0xffff, 0xffff, 0xffff, 0xffff, 0xffff, 0xffff, 0xffff, 0xffff, 0xffff,
  0xffff, 0xffff, 0xffff, 0xffff, 0xffff, 0xffff, 0xffff, 0xffff, 0xffff, 0xffff, 0xffff, 0xffff, 0xffff, 0xffff, 0xffff, 0xffff, 0xffff, 0xffff, 0xffff, 0xffff, 0xffff, 0xffff, 0xffff, 0xffff, 0xffff, 0xffff, 0xffff, 0xffff, 0xffff, 0xffff, 0xffff, 0xffff, 0xffff, 0xffff, 0xffff, 0xffff, 0xffff, 0xffff, 0xffff, 0xffff, 0xffff, 0xffff, 0xffff, 0xffff, 0xffff, 0xffff, 0xffff, 0xffff, 0xffff, 0xffff, 0xffff, 0xffff, 0xffff, 0xffff, 0xffff, 0xffff, 0xffff, 0xffff, 0xffff, 0xffff,
  0xffff, 0xffff, 0xffff, 0xffff, 0xffff, 0xffff, 0xffff, 0xffff, 0xffff, 0xffff, 0xffff, 0xffff, 0xffff, 0xffff, 0xffff, 0xffff, 0xffff, 0xffff, 0xffff, 0xffff, 0xffff, 0xffff, 0xffff, 0xffff, 0xffff, 0xffff, 0xffff, 0xffff, 0xffff, 0xffff, 0xffff, 0xffff, 0xffff, 0xffff, 0xffff, 0xffff, 0xffff, 0xffff, 0xffff, 0xffff, 0xffff, 0xffff, 0xffff, 0xffff, 0xffff, 0xffff, 0xffff, 0xffff, 0xffff, 0xffff, 0xffff, 0xffff, 0xffff, 0xffff, 0xffff, 0xffff, 0xffff, 0xffff, 0xffff, 0xffff,
  0xffff, 0xffff, 0xffff, 0xffff, 0xffff, 0xffff, 0xffff, 0xffff, 0xffff, 0xffff, 0xffff, 0xffff, 0xffff, 0xffff, 0xffff, 0xffff, 0xffff, 0xffff, 0xffff, 0xffff, 0xffff, 0xffff, 0xffff, 0xffff, 0xffff, 0xffff, 0xffff, 0xffff, 0xffff, 0xffff, 0xffff, 0xffff, 0xffff, 0xffff, 0xffff, 0xffff, 0xffff, 0xffff, 0xffff, 0xffff, 0xffff, 0xffff, 0xffff, 0xffff, 0xffff, 0xffff, 0xffff, 0xffff, 0xffff, 0xffff, 0xffff, 0xffff, 0xffff, 0xffff, 0xffff, 0xffff, 0xffff, 0xffff, 0xffff, 0xffff,
  0xffff, 0xffff, 0xffff, 0xffff, 0xffff, 0xffff, 0xffff, 0xffff, 0xffff, 0xffff, 0xffff, 0xffff, 0xffff, 0xffff, 0xffff, 0xffff, 0xffff, 0xffff, 0xffff, 0xffff, 0xffff, 0xffff, 0xffff, 0xffff, 0xffff, 0xffff, 0xffff, 0xffff, 0xffff, 0xffff, 0xffff, 0xffff, 0xffff, 0xffff, 0xffff, 0xffff, 0xffff, 0xffff, 0xffff, 0xffff, 0xffff, 0xffff, 0xffff, 0xffff, 0xffff, 0xffff, 0xffff, 0xffff, 0xffff, 0xffff, 0xffff, 0xffff, 0xffff, 0xffff, 0xffff, 0xffff, 0xffff, 0xffff, 0xffff, 0xffff,
  0xffff, 0xffff, 0xffff, 0xffff, 0xffff, 0xffff, 0xffff, 0xffff, 0xffff, 0xffff, 0xffff, 0xffff, 0xffff, 0xffff, 0xffff, 0xffff, 0xffff, 0xffff, 0xffff, 0xffff, 0xffff, 0xffff, 0xffff, 0xffff, 0xffff, 0xffff, 0xffff, 0xffff, 0xffff, 0xffff, 0xffff, 0xffff, 0xffff, 0xffff, 0xffff, 0xffff, 0xffff, 0xffff, 0xffff, 0xffff, 0xffff, 0xffff, 0xffff, 0xffff, 0xffff, 0xffff, 0xffff, 0xffff, 0xffff, 0xffff, 0xffff, 0xffff, 0xffff, 0xffff, 0xffff, 0xffff, 0xffff, 0xffff, 0xffff, 0xffff,
  0xffff, 0xffff, 0xffff, 0xffff, 0xffff, 0xffff, 0xffff, 0xffff, 0xffff, 0xffff, 0xffff, 0xffff, 0xffff, 0xffff, 0xffff, 0xffff, 0xffff, 0xffff, 0xffff, 0xffff, 0xffff, 0xffff, 0xffff, 0xffff, 0xffff, 0xffff, 0xffff, 0xffff, 0xffff, 0xffff, 0xffff, 0xffff, 0xffff, 0xffff, 0xffff, 0xffff, 0xffff, 0xffff, 0xffff, 0xffff, 0xffff, 0xffff, 0xffff, 0xffff, 0xffff, 0xffff, 0xffff, 0xffff, 0xffff, 0xffff, 0xffff, 0xffff, 0xffff, 0xffff, 0xffff, 0xffff, 0xffff, 0xffff, 0xffff, 0xffff,
  0xffff, 0xffff, 0xffff, 0xffff, 0xffff, 0xffff, 0xffff, 0xffff, 0xffff, 0xffff, 0xffff, 0xffff, 0xffff, 0xffff, 0xffff, 0xffff, 0xffff, 0xffff, 0xffff, 0xffff, 0xffff, 0xffff, 0xffff, 0xffff, 0xffff, 0xffff, 0xffff, 0xffff, 0xffff, 0xffff, 0xffff, 0xffff, 0xffff, 0xffff, 0xffff, 0xffff, 0xffff, 0xffff, 0xffff, 0xffff, 0xffff, 0xffff, 0xffff, 0xffff, 0xffff, 0xffff, 0xffff, 0xffff, 0xffff, 0xffff, 0xffff, 0xffff, 0xffff, 0xffff, 0xffff, 0xffff, 0xffff, 0xffff, 0xffff, 0xffff,
  0xffff, 0xffff, 0xffff, 0xffff, 0xffff, 0xffff, 0xffff, 0xffff, 0xffff, 0xffff, 0xffff, 0xffff, 0xffff, 0xffff, 0xffff, 0xffff, 0xffff, 0xffff, 0xffff, 0xffff, 0xffff, 0xffff, 0xffff, 0xffff, 0xffff, 0xffff, 0xffff, 0xffff, 0xffff, 0xffff, 0xffff, 0xffff, 0xffff, 0xffff, 0xffff, 0xffff, 0xffff, 0xffff, 0xffff, 0xffff, 0xffff, 0xffff, 0xffff, 0xffff, 0xffff, 0xffff, 0xffff, 0xffff, 0xffff, 0xffff, 0xffff, 0xffff, 0xffff, 0xffff, 0xffff, 0xffff, 0xffff, 0xffff, 0xffff, 0xffff
};
// array size is 7200
static const uint16_t img1[][60*60/2]  = {
  0xffff, 0xffff, 0xffff, 0xffff, 0xffff, 0xffff, 0xffff, 0xffff, 0xffff, 0xffff, 0xffff, 0xffff, 0xffff, 0xffff, 0xffff, 0xffff, 0xffff, 0xffff, 0xffff, 0xffff, 0xffff, 0xffff, 0xffff, 0xffff, 0xffff, 0xffff, 0xffff, 0xffff, 0xffff, 0xffff, 0xffff, 0xffff, 0xffff, 0xffff, 0xffff, 0xffff, 0xffff, 0xffff, 0xffff, 0xffff, 0xffff, 0xffff, 0xffff, 0xffff, 0xffff, 0xffff, 0xffff, 0xffff, 0xffff, 0xffff, 0xffff, 0xffff, 0xffff, 0xffff, 0xffff, 0xffff, 0xffff, 0xffff, 0xffff, 0xffff,
  0xffff, 0xffff, 0xffff, 0xffff, 0xffff, 0xffff, 0xffff, 0xffff, 0xffff, 0xffff, 0xffff, 0xffff, 0xffff, 0xffff, 0xffff, 0xffff, 0xffff, 0xffff, 0xffff, 0xffff, 0xffff, 0xffff, 0xffff, 0xffff, 0xffff, 0xffff, 0xffff, 0xffff, 0xffff, 0xffff, 0xffff, 0xffff, 0xffff, 0xffff, 0xffff, 0xffff, 0xffff, 0xffff, 0xffff, 0xffff, 0xffff, 0xffff, 0xffff, 0xffff, 0xffff, 0xffff, 0xffff, 0xffff, 0xffff, 0xffff, 0xffff, 0xffff, 0xffff, 0xffff, 0xffff, 0xffff, 0xffff, 0xffff, 0xffff, 0xffff,
  0xffff, 0xffff, 0xffff, 0xffff, 0xffff, 0xffff, 0xffff, 0xffff, 0xffff, 0xffff, 0xffff, 0xffff, 0xffff, 0xffff, 0xffff, 0xffff, 0xffff, 0xffff, 0xffff, 0xffff, 0xffff, 0xffff, 0xffff, 0xffff, 0xffff, 0xffff, 0xffff, 0xffff, 0xffff, 0xffff, 0xffff, 0xffff, 0xffff, 0xffff, 0xffff, 0xffff, 0xffff, 0xffff, 0xffff, 0xffff, 0xffff, 0xffff, 0xffff, 0xffff, 0xffff, 0xffff, 0xffff, 0xffff, 0xffff, 0xffff, 0xffff, 0xffff, 0xffff, 0xffff, 0xffff, 0xffff, 0xffff, 0xffff, 0xffff, 0xffff,
  0xffff, 0xffff, 0xffff, 0xffff, 0xffff, 0xffff, 0xffff, 0xffff, 0xffff, 0xffff, 0xffff, 0xffff, 0xffff, 0xffff, 0xffff, 0xffff, 0xffff, 0xffff, 0xffff, 0xffff, 0xffff, 0xffff, 0xffff, 0xffff, 0xffff, 0xffff, 0xffff, 0xffff, 0xffff, 0xffff, 0xffff, 0xffff, 0xffff, 0xffff, 0xffff, 0xffff, 0xffff, 0xffff, 0xffff, 0xffff, 0xffff, 0xffff, 0xffff, 0xffff, 0xffff, 0xffff, 0xffff, 0xffff, 0xffff, 0xffff, 0xffff, 0xffff, 0xffff, 0xffff, 0xffff, 0xffff, 0xffff, 0xffff, 0xffff, 0xffff,
  0xffff, 0xffff, 0xffff, 0xffff, 0xffff, 0xffff, 0xffff, 0xffff, 0xffff, 0xffff, 0xffff, 0xffff, 0xffff, 0xffff, 0xffff, 0xffff, 0xffff, 0xffff, 0xffff, 0xffff, 0xffff, 0xffff, 0xffff, 0xffff, 0xffff, 0xffff, 0xffff, 0xffff, 0xffff, 0xffff, 0xffff, 0xffff, 0xffff, 0xffff, 0xffff, 0xffff, 0xffff, 0xffff, 0xffff, 0xffff, 0xffff, 0xffff, 0xffff, 0xffff, 0xffff, 0xffff, 0xffff, 0xffff, 0xffff, 0xffff, 0xffff, 0xffff, 0xffff, 0xffff, 0xffff, 0xffff, 0xffff, 0xffff, 0xffff, 0xffff,
  0xffff, 0xffff, 0xffff, 0xffff, 0xffff, 0xffff, 0xffff, 0xffff, 0xffff, 0xffff, 0xffff, 0xffff, 0xffff, 0xffff, 0xffff, 0xffff, 0xffff, 0xffff, 0xffff, 0xffff, 0xffff, 0xffff, 0xffff, 0xffff, 0xffff, 0xffff, 0xffff, 0xffff, 0xffff, 0xffff, 0xffff, 0xffff, 0xffff, 0xffff, 0xffff, 0xffff, 0xffff, 0xffff, 0xffff, 0xffff, 0xffff, 0xffff, 0xffff, 0xffff, 0xffff, 0xffff, 0xffff, 0xffff, 0xffff, 0xffff, 0xffff, 0xffff, 0xffff, 0xffff, 0xffff, 0xffff, 0xffff, 0xffff, 0xffff, 0xffff,
  0xffff, 0xffff, 0xffff, 0xffff, 0xffff, 0xffff, 0xffff, 0xffff, 0xffff, 0xffff, 0xffff, 0xffff, 0xffff, 0xffff, 0xffff, 0xffff, 0xffff, 0xffff, 0xffff, 0xffff, 0xffff, 0xffff, 0xffff, 0xffff, 0xffff, 0xffff, 0xffff, 0xffff, 0xffff, 0xffff, 0xffff, 0xffff, 0xffff, 0xffff, 0xffff, 0xffff, 0xffff, 0xffff, 0xffff, 0xffff, 0xffff, 0xffff, 0xffff, 0xffff, 0xffff, 0xffff, 0xffff, 0xffff, 0xffff, 0xffff, 0xffff, 0xffff, 0xffff, 0xffff, 0xffff, 0xffff, 0xffff, 0xffff, 0xffff, 0xffff,
  0xffff, 0xffff, 0xffff, 0xffff, 0xffff, 0xffff, 0xffff, 0xffff, 0xffff, 0xffff, 0xffff, 0xffff, 0xffff, 0xffff, 0xffff, 0xffff, 0xffff, 0xffff, 0xffff, 0xffff, 0xffff, 0xffff, 0xffff, 0xffff, 0xffff, 0xffff, 0xffff, 0xffff, 0xffff, 0xffff, 0xffff, 0xffff, 0xffff, 0xffff, 0xffff, 0xffff, 0xffff, 0xffff, 0xffff, 0xffff, 0xffff, 0xffff, 0xffff, 0xffff, 0xffff, 0xffff, 0xffff, 0xffff, 0xffff, 0xffff, 0xffff, 0xffff, 0xffff, 0xffff, 0xffff, 0xffff, 0xffff, 0xffff, 0xffff, 0xffff,
  0xffff, 0xffff, 0xffff, 0xffff, 0xffff, 0xffff, 0xffff, 0xffff, 0xffff, 0xffff, 0xffff, 0xffff, 0xffff, 0xffff, 0xffff, 0xffff, 0xffff, 0xffff, 0xffff, 0xffff, 0xffff, 0xffff, 0xffff, 0xffff, 0xffff, 0xffff, 0xffff, 0xffff, 0xffff, 0xffff, 0xffff, 0xffff, 0xffff, 0xffff, 0xffff, 0xffff, 0xffff, 0xffff, 0xffff, 0xffff, 0xffff, 0xffff, 0xffff, 0xffff, 0xffff, 0xffff, 0xffff, 0xffff, 0xffff, 0xffff, 0xffff, 0xffff, 0xffff, 0xffff, 0xffff, 0xffff, 0xffff, 0xffff, 0xffff, 0xffff,
  0xffff, 0xffff, 0xffff, 0xffff, 0xffff, 0xffff, 0xffff, 0xffff, 0xffff, 0xffff, 0xffff, 0xffff, 0xffff, 0xffff, 0xffff, 0xffff, 0xffff, 0xffff, 0xffff, 0xffff, 0xffff, 0xffff, 0xffff, 0xffff, 0xffff, 0xffff, 0xffff, 0xffff, 0xffff, 0xffff, 0xffff, 0xffff, 0xffff, 0xffff, 0xffff, 0xffff, 0xffff, 0xffff, 0xffff, 0xffff, 0xffff, 0xffff, 0xffff, 0xffff, 0xffff, 0xffff, 0xffff, 0xffff, 0xffff, 0xffff, 0xffff, 0xffff, 0xffff, 0xffff, 0xffff, 0xffff, 0xffff, 0xffff, 0xffff, 0xffff,
  0xffff, 0xffff, 0xffff, 0xffff, 0xffff, 0xffff, 0xffff, 0xffff, 0xffff, 0xffff, 0xffff, 0xffff, 0xffff, 0xffff, 0xffff, 0xffff, 0xffff, 0xffff, 0xffff, 0xffff, 0xffff, 0xffff, 0xffff, 0xffff, 0xffff, 0xffff, 0xffff, 0xffff, 0xffff, 0xffff, 0xffff, 0xffff, 0xffff, 0xffff, 0xffff, 0xffff, 0xffff, 0xffff, 0xffff, 0xffff, 0xffff, 0xffff, 0xffff, 0xffff, 0xffff, 0xffff, 0xffff, 0xffff, 0xffff, 0xffff, 0xffff, 0xffff, 0xffff, 0xffff, 0xffff, 0xffff, 0xffff, 0xffff, 0xffff, 0xffff,
  0xffff, 0xffff, 0xffff, 0xffff, 0xffff, 0xffff, 0xffff, 0xffff, 0xffff, 0xffff, 0xffff, 0xffff, 0xffff, 0xffff, 0xffff, 0xffff, 0xffff, 0xffff, 0xffff, 0xffff, 0xffff, 0xffff, 0xffff, 0xffff, 0xffff, 0xffff, 0xffff, 0xffff, 0xffff, 0xffff, 0xffff, 0xffff, 0xffff, 0xffff, 0xffff, 0xffff, 0xffff, 0xffff, 0xffff, 0xffff, 0xffff, 0xffff, 0xffff, 0xffff, 0xffff, 0xffff, 0xffff, 0xffff, 0xffff, 0xffff, 0xffff, 0xffff, 0xffff, 0xffff, 0xffff, 0xffff, 0xffff, 0xffff, 0xffff, 0xffff,
  0xffff, 0xffff, 0xffff, 0xffff, 0xffff, 0xffff, 0xffff, 0xffff, 0xffff, 0xffff, 0xffff, 0xffff, 0xffff, 0xffff, 0xffff, 0xffff, 0xffff, 0xffff, 0xffff, 0xffff, 0xffff, 0xffff, 0xffff, 0xffff, 0xffff, 0xffff, 0xffff, 0xffff, 0xffff, 0xffff, 0xffff, 0xffff, 0xffff, 0xffff, 0xffff, 0xffff, 0xffff, 0xffff, 0xffff, 0xffff, 0xffff, 0xffff, 0xffff, 0xffff, 0xffff, 0xffff, 0xffff, 0xffff, 0xffff, 0xffff, 0xffff, 0xffff, 0xffff, 0xffff, 0xffff, 0xffff, 0xffff, 0xffff, 0xffff, 0xffff,
  0xffff, 0xffff, 0xffff, 0xffff, 0xffff, 0xffff, 0xffff, 0xffff, 0xffff, 0xffff, 0xffff, 0xffff, 0xffff, 0xffff, 0xffff, 0xffff, 0xffff, 0xffff, 0xffff, 0xffff, 0xffff, 0xffff, 0xffff, 0xffff, 0xffff, 0xffff, 0xffff, 0xffff, 0xffff, 0xffff, 0xffff, 0xffff, 0xffff, 0xffff, 0xffff, 0xffff, 0xffff, 0xffff, 0xffff, 0xffff, 0xffff, 0xffff, 0xffff, 0xffff, 0xffff, 0xffff, 0xffff, 0xffff, 0xffff, 0xffff, 0xffff, 0xffff, 0xffff, 0xffff, 0xffff, 0xffff, 0xffff, 0xffff, 0xffff, 0xffff,
  0xffff, 0xffff, 0xffff, 0xffff, 0xffff, 0xffff, 0xffff, 0xffff, 0xffff, 0xffff, 0xffff, 0xffff, 0xffff, 0xffff, 0xffff, 0xffff, 0xffff, 0xffff, 0xffff, 0xffff, 0xffff, 0xffff, 0xffff, 0xffff, 0xffff, 0xffff, 0xffff, 0xffff, 0xffff, 0xffff, 0xffff, 0xffff, 0xffff, 0xffff, 0xffff, 0xffff, 0xffff, 0xffff, 0xffff, 0xffff, 0xffff, 0xffff, 0xffff, 0xffff, 0xffff, 0xffff, 0xffff, 0xffff, 0xffff, 0xffff, 0xffff, 0xffff, 0xffff, 0xffff, 0xffff, 0xffff, 0xffff, 0xffff, 0xffff, 0xffff,
  0xffff, 0xffff, 0xffff, 0xffff, 0xffff, 0xffff, 0xffff, 0xffff, 0xffff, 0xffff, 0xffff, 0xffff, 0xffff, 0xffff, 0xffff, 0xffff, 0xffff, 0xffff, 0xffff, 0xffff, 0xffff, 0xffff, 0xffff, 0xffff, 0xffff, 0xffff, 0xffff, 0xffff, 0xffff, 0xffff, 0xffff, 0xffff, 0xffff, 0xffff, 0xffff, 0xffff, 0xffff, 0xffff, 0xffff, 0xffff, 0xffff, 0xffff, 0xffff, 0xffff, 0xffff, 0xffff, 0xffff, 0xffff, 0xffff, 0xffff, 0xffff, 0xffff, 0xffff, 0xffff, 0xffff, 0xffff, 0xffff, 0xffff, 0xffff, 0xffff,
  0xffff, 0xffff, 0xffff, 0xffff, 0xffff, 0xffff, 0xffff, 0xffff, 0xffff, 0xffff, 0xffff, 0xffff, 0xffff, 0xffff, 0xffff, 0xffff, 0xffff, 0xffff, 0xffff, 0xffff, 0xffff, 0xffff, 0xffff, 0xffff, 0xffff, 0xffff, 0xffff, 0xffff, 0xffff, 0xffff, 0xffff, 0xffff, 0xffff, 0xffff, 0xffff, 0xffff, 0xffff, 0xffff, 0xffff, 0xffff, 0xffff, 0xffff, 0xffff, 0xffff, 0xffff, 0xffff, 0xffff, 0xffff, 0xffff, 0xffff, 0xffff, 0xffff, 0xffff, 0xffff, 0xffff, 0xffff, 0xffff, 0xffff, 0xffff, 0xffff,
  0xffff, 0xffff, 0xffff, 0xffff, 0xffff, 0xffff, 0xffff, 0xffff, 0xffff, 0xffff, 0xffff, 0xffff, 0xffff, 0xffff, 0xffff, 0xffff, 0xffff, 0xffff, 0xffff, 0xffff, 0xffff, 0xffff, 0xffff, 0xffff, 0xffff, 0xffff, 0xffff, 0xffff, 0xffff, 0xffff, 0xffff, 0xffff, 0xffff, 0xffff, 0xffff, 0xffff, 0xffff, 0xffff, 0xffff, 0xffff, 0xffff, 0xffff, 0xffff, 0xffff, 0xffff, 0xffff, 0xffff, 0xffff, 0xffff, 0xffff, 0xffff, 0xffff, 0xffff, 0xffff, 0xffff, 0xffff, 0xffff, 0xffff, 0xffff, 0xffff,
  0xffff, 0xffff, 0xffff, 0xffff, 0xffff, 0xffff, 0xffff, 0xffff, 0xffff, 0xffff, 0xffff, 0xffff, 0xffff, 0xffff, 0xffff, 0xffff, 0xffff, 0xffff, 0xffff, 0xffff, 0xffff, 0xffff, 0xffff, 0xffff, 0xffff, 0xffff, 0xffff, 0xffff, 0xffff, 0xffff, 0xffff, 0xffff, 0xffff, 0xffff, 0xffff, 0xffff, 0xffff, 0xffff, 0xffff, 0xffff, 0xffff, 0xffff, 0xffff, 0xffff, 0xffff, 0xffff, 0xffff, 0xffff, 0xffff, 0xffff, 0xffff, 0xffff, 0xffff, 0xffff, 0xffff, 0xffff, 0xffff, 0xffff, 0xffff, 0xffff,
  0xffff, 0xffff, 0xffff, 0xffff, 0xffff, 0xffff, 0xffff, 0xffff, 0xffff, 0xffff, 0xffff, 0xffff, 0xffff, 0xffff, 0xffff, 0xffff, 0xffff, 0xffff, 0xffff, 0xffff, 0xffff, 0xffff, 0xffff, 0xffff, 0xffff, 0xffff, 0xffff, 0xffff, 0xffff, 0xffff, 0xffff, 0xffff, 0xffff, 0xffff, 0xffff, 0xffff, 0xffff, 0xffff, 0xffff, 0xffff, 0xffff, 0xffff, 0xffff, 0xffff, 0xffff, 0xffff, 0xffff, 0xffff, 0xffff, 0xffff, 0xffff, 0xffff, 0xffff, 0xffff, 0xffff, 0xffff, 0xffff, 0xffff, 0xffff, 0xffff,
  0xffff, 0xffff, 0xffff, 0xffff, 0xffff, 0xffff, 0xffff, 0xffff, 0xffff, 0xffff, 0xffff, 0xffff, 0xffff, 0xffff, 0xffff, 0xffff, 0xffff, 0xffff, 0xffff, 0xffff, 0xffff, 0xffff, 0xffff, 0xffff, 0xffff, 0xffff, 0xffff, 0xffff, 0xffff, 0xffff, 0xffff, 0xffff, 0xffff, 0xffff, 0xffff, 0xffff, 0xffff, 0xffff, 0xffff, 0xffff, 0xffff, 0xffff, 0xffff, 0xffff, 0xffff, 0xffff, 0xffff, 0xffff, 0xffff, 0xffff, 0xffff, 0xffff, 0xffff, 0xffff, 0xffff, 0xffff, 0xffff, 0xffff, 0xffff, 0xffff,
  0xffff, 0xffff, 0xffff, 0xffff, 0xffff, 0xffff, 0xffff, 0xffff, 0xffff, 0xffff, 0xffff, 0xffff, 0xffff, 0xffff, 0xffff, 0xffff, 0xffff, 0xffff, 0xffff, 0xffff, 0xffff, 0xffff, 0xffff, 0xffff, 0xffff, 0xffff, 0xffff, 0xffff, 0xffff, 0xffff, 0xffff, 0xffff, 0xffff, 0xffff, 0xffff, 0xffff, 0xffff, 0xffff, 0xffff, 0xffff, 0xffff, 0xffff, 0xffff, 0xffff, 0xffff, 0xffff, 0xffff, 0xffff, 0xffff, 0xffff, 0xffff, 0xffff, 0xffff, 0xffff, 0xffff, 0xffff, 0xffff, 0xffff, 0xffff, 0xffff,
  0xffff, 0xffff, 0xffff, 0xffff, 0xffff, 0xffff, 0xffff, 0xffff, 0xffff, 0xffff, 0xffff, 0xffff, 0xffff, 0xffff, 0xffff, 0xffff, 0xffff, 0xffff, 0xffff, 0xffff, 0xffff, 0xffff, 0xffff, 0xffff, 0xffff, 0xffff, 0xffff, 0xffff, 0xffff, 0xffff, 0xffff, 0xffff, 0xffff, 0xffff, 0xffff, 0xffff, 0xffff, 0xffff, 0xffff, 0xffff, 0xffff, 0xffff, 0xffff, 0xffff, 0xffff, 0xffff, 0xffff, 0xffff, 0xffff, 0xffff, 0xffff, 0xffff, 0xffff, 0xffff, 0xffff, 0xffff, 0xffff, 0xffff, 0xffff, 0xffff,
  0xffff, 0xffff, 0xffff, 0xffff, 0xffff, 0xffff, 0xffff, 0xffff, 0xffff, 0xffff, 0xffff, 0xffff, 0xffff, 0xffff, 0xffff, 0xffff, 0xffff, 0xffff, 0xffff, 0xffff, 0xffff, 0xffff, 0xffff, 0xffff, 0xffff, 0xffff, 0xffff, 0xffff, 0xffff, 0xffff, 0xffff, 0xffff, 0xffff, 0xffff, 0xffff, 0xffff, 0xffff, 0xffff, 0xffff, 0xffff, 0xffff, 0xffff, 0xffff, 0xffff, 0xffff, 0xffff, 0xffff, 0xffff, 0xffff, 0xffff, 0xffff, 0xffff, 0xffff, 0xffff, 0xffff, 0xffff, 0xffff, 0xffff, 0xffff, 0xffff,
  0xffff, 0xffff, 0xffff, 0xffff, 0xffff, 0xffff, 0xffff, 0xffff, 0xffff, 0xffff, 0xffff, 0xffff, 0xffff, 0xffff, 0xffff, 0xffff, 0xffff, 0xffff, 0xffff, 0xffff, 0xffff, 0xffff, 0xffff, 0xffff, 0xffff, 0xffff, 0xffff, 0xffff, 0xffff, 0xffff, 0xffff, 0xffff, 0xffff, 0xffff, 0xffff, 0xffff, 0xffff, 0xffff, 0xffff, 0xffff, 0xffff, 0xffff, 0xffff, 0xffff, 0xffff, 0xffff, 0xffff, 0xffff, 0xffff, 0xffff, 0xffff, 0xffff, 0xffff, 0xffff, 0xffff, 0xffff, 0xffff, 0xffff, 0xffff, 0xffff,
  0xffff, 0xffff, 0xffff, 0xffff, 0xffff, 0xffff, 0xffff, 0xffff, 0xffff, 0xffff, 0xffff, 0xffff, 0xffff, 0xffff, 0xffff, 0xffff, 0xffff, 0xffff, 0xffff, 0xffff, 0xffff, 0xffff, 0xffff, 0xffff, 0xffff, 0xffff, 0xffff, 0xffff, 0xffff, 0xffff, 0xffff, 0xffff, 0xffff, 0xffff, 0xffff, 0xffff, 0xffff, 0xffff, 0xffff, 0xffff, 0xffff, 0xffff, 0xffff, 0xffff, 0xffff, 0xffff, 0xffff, 0xffff, 0xffff, 0xffff, 0xffff, 0xffff, 0xffff, 0xffff, 0xffff, 0xffff, 0xffff, 0xffff, 0xffff, 0xffff,
  0xffff, 0xffff, 0xffff, 0xffff, 0xffff, 0xffff, 0xffff, 0xffff, 0xffff, 0xffff, 0xffff, 0xffff, 0xffff, 0xffff, 0xffff, 0xffff, 0xffff, 0xffff, 0xffff, 0xffff, 0xffff, 0xffff, 0xffff, 0xffff, 0xffff, 0xffff, 0xffff, 0xffff, 0xffff, 0xffff, 0xffff, 0xffff, 0xffff, 0xffff, 0xffff, 0xffff, 0xffff, 0xffff, 0xffff, 0xffff, 0xffff, 0xffff, 0xffff, 0xffff, 0xffff, 0xffff, 0xffff, 0xffff, 0xffff, 0xffff, 0xffff, 0xffff, 0xffff, 0xffff, 0xffff, 0xffff, 0xffff, 0xffff, 0xffff, 0xffff,
  0xffff, 0xffff, 0xffff, 0xffff, 0xffff, 0xffff, 0xffff, 0xffff, 0xffff, 0xffff, 0xffff, 0xffff, 0xffff, 0xffff, 0xffff, 0xffff, 0xffff, 0xffff, 0xffff, 0xffff, 0xffff, 0xffff, 0xffff, 0xffff, 0xffff, 0xffff, 0xffff, 0xffff, 0xffff, 0xffff, 0xffff, 0xffff, 0xffff, 0xffff, 0xffff, 0xffff, 0xffff, 0xffff, 0xffff, 0xffff, 0xffff, 0xffff, 0xffff, 0xffff, 0xffff, 0xffff, 0xffff, 0xffff, 0xffff, 0xffff, 0xffff, 0xffff, 0xffff, 0xffff, 0xffff, 0xffff, 0xffff, 0xffff, 0xffff, 0xffff,
  0xffff, 0xffff, 0xffff, 0xffff, 0xffff, 0xffff, 0xffff, 0xffff, 0xffff, 0xffff, 0xffff, 0xffff, 0xffff, 0xffff, 0xffff, 0xffff, 0xffff, 0xffff, 0xffff, 0xffff, 0xffff, 0xffff, 0xffff, 0xffff, 0xffff, 0xffff, 0xffff, 0xffff, 0xffff, 0xffff, 0xffff, 0xffff, 0xffff, 0xffff, 0xffff, 0xffff, 0xffff, 0xffff, 0xffff, 0xffff, 0xffff, 0xffff, 0xffff, 0xffff, 0xffff, 0xffff, 0xffff, 0xffff, 0xffff, 0xffff, 0xffff, 0xffff, 0xffff, 0xffff, 0xffff, 0xffff, 0xffff, 0xffff, 0xffff, 0xffff,
  0xffff, 0xffff, 0xffff, 0xffff, 0xffff, 0xffff, 0xffff, 0xffff, 0xffff, 0xffff, 0xffff, 0xffff, 0xffff, 0xffff, 0xffff, 0xffff, 0xffff, 0xffff, 0xffff, 0xffff, 0xffff, 0xffff, 0xffff, 0xffff, 0xffff, 0xffff, 0xffff, 0xffff, 0xffff, 0xffff, 0xffff, 0xffff, 0xffff, 0xffff, 0xffff, 0xffff, 0xffff, 0xffff, 0xffff, 0xffff, 0xffff, 0xffff, 0xffff, 0xffff, 0xffff, 0xffff, 0xffff, 0xffff, 0xffff, 0xffff, 0xffff, 0xffff, 0xffff, 0xffff, 0xffff, 0xffff, 0xffff, 0xffff, 0xffff, 0xffff,
  0xffff, 0xffff, 0xffff, 0xffff, 0xffff, 0xffff, 0xffff, 0xffff, 0xffff, 0xffff, 0xffff, 0xffff, 0xffff, 0xffff, 0xffff, 0xffff, 0xffff, 0xffff, 0xffff, 0xffff, 0xffff, 0xffff, 0xffff, 0xffff, 0xffff, 0xffff, 0xffff, 0xffff, 0xffff, 0xffff, 0xffff, 0xffff, 0xffff, 0xffff, 0xffff, 0xffff, 0xffff, 0xffff, 0xffff, 0xffff, 0xffff, 0xffff, 0xffff, 0xffff, 0xffff, 0xffff, 0xffff, 0xffff, 0xffff, 0xffff, 0xffff, 0xffff, 0xffff, 0xffff, 0xffff, 0xffff, 0xffff, 0xffff, 0xffff, 0xffff,
  0xffff, 0xffff, 0xffff, 0xffff, 0xffff, 0xffff, 0xffff, 0xffff, 0xffff, 0xffff, 0xffff, 0xffff, 0xffff, 0xffff, 0xffff, 0xffff, 0xffff, 0xffff, 0xffff, 0xffff, 0xffff, 0xffff, 0xffff, 0xffff, 0xffff, 0xffff, 0xdef7, 0xbdef, 0x7bd7, 0x5ac7, 0x59c7, 0x59c7, 0x59c7, 0x7bcf, 0xbde7, 0xdeef, 0xfff7, 0xffff, 0xffff, 0xffff, 0xffff, 0xffff, 0xffff, 0xffff, 0xffff, 0xffff, 0xffff, 0xffff, 0xffff, 0xffff, 0xffff, 0xffff, 0xffff, 0xffff, 0xffff, 0xffff, 0xffff, 0xffff, 0xffff, 0xffff,
  0xffff, 0xffff, 0xffff, 0xffff, 0xffff, 0xffff, 0xffff, 0xffff, 0xffff, 0xffff, 0xffff, 0xffff, 0xffff, 0xffff, 0xffff, 0xffff, 0xffff, 0xffff, 0xffff, 0xffff, 0xffff, 0xffff, 0xffff, 0xffff, 0xffff, 0xffff, 0xbce7, 0x59bf, 0x7176, 0xed4d, 0xed4d, 0xed4d, 0xed4d, 0x516e, 0x17af, 0x7acf, 0xbde7, 0xdef7, 0xffff, 0xffff, 0xffff, 0xffff, 0xffff, 0xffff, 0xffff, 0xffff, 0xffff, 0xffff, 0xffff, 0xffff, 0xffff, 0xffff, 0xffff, 0xffff, 0xffff, 0xffff, 0xffff, 0xffff, 0xffff, 0xffff,
  0xffff, 0xffff, 0xffff, 0xffff, 0xffff, 0xffff, 0xffff, 0xffff, 0xffff, 0xffff, 0xffff, 0xffff, 0xffff, 0xffff, 0xffff, 0xffff, 0xffff, 0xffff, 0xffff, 0xffff, 0xffff, 0xffff, 0xffff, 0xffff, 0xdef7, 0xbde7, 0x38b7, 0x9386, 0xed45, 0x8925, 0x8925, 0x8925, 0x8925, 0xcc3d, 0x7176, 0xd59e, 0x5ac7, 0xbde7, 0xffff, 0xffff, 0xffff, 0xffff, 0xffff, 0xffff, 0xffff, 0xffff, 0xffff, 0xffff, 0xffff, 0xffff, 0xffff, 0xffff, 0xffff, 0xffff, 0xffff, 0xffff, 0xffff, 0xffff, 0xffff, 0xffff,
  0xffff, 0xffff, 0xffff, 0xffff, 0xffff, 0xffff, 0xffff, 0xffff, 0xffff, 0xffff, 0xffff, 0xffff, 0xffff, 0xffff, 0xffff, 0xffff, 0xffff, 0xffff, 0xffff, 0xffff, 0xffff, 0xffff, 0xffff, 0xffff, 0xbce7, 0x59c7, 0x516e, 0xab35, 0x8a2d, 0x8925, 0x8925, 0x8925, 0x8925, 0x8a25, 0xaa35, 0x2f5e, 0xd59e, 0x7bcf, 0xffff, 0xffff, 0xffff, 0xffff, 0xffff, 0xffff, 0xffff, 0xffff, 0xffff, 0xffff, 0xffff, 0xffff, 0xffff, 0xffff, 0xffff, 0xffff, 0xffff, 0xffff, 0xffff, 0xffff, 0xffff, 0xffff,
  0xffff, 0xffff, 0xffff, 0xffff, 0xffff, 0xffff, 0xffff, 0xffff, 0xffff, 0xffff, 0xffff, 0xffff, 0xffff, 0xffff, 0xffff, 0xffff, 0xffff, 0xffff, 0xffff, 0xffff, 0xffff, 0xffff, 0xffff, 0xffff, 0x39bf, 0x9386, 0xed45, 0x8925, 0x8925, 0x8925, 0x8925, 0x8925, 0x8925, 0x8925, 0x8925, 0xcc3d, 0x5066, 0x38b7, 0xffff, 0xffff, 0xffff, 0xffff, 0xffff, 0xffff, 0xffff, 0xffff, 0xffff, 0xffff, 0xffff, 0xffff, 0xffff, 0xffff, 0xffff, 0xffff, 0xffff, 0xffff, 0xffff, 0xffff, 0xffff, 0xffff,
  0xffff, 0xffff, 0xffff, 0xffff, 0xffff, 0xffff, 0xffff, 0xffff, 0xffff, 0xffff, 0xffff, 0xffff, 0xffff, 0xffff, 0xffff, 0xffff, 0xffff, 0xffff, 0xffff, 0xffff, 0xffff, 0xffff, 0xffff, 0xffff, 0xb386, 0xaa2d, 0x8925, 0x8925, 0x8925, 0x8925, 0x8925, 0x8925, 0x8925, 0x8925, 0x8925, 0x8925, 0x8a2d, 0xd596, 0xffff, 0xffff, 0xffff, 0xffff, 0xffff, 0xffff, 0xffff, 0xffff, 0xffff, 0xffff, 0xffff, 0xffff, 0xffff, 0xffff, 0xffff, 0xffff, 0xffff, 0xffff, 0xffff, 0xffff, 0xffff, 0xffff,
  0xffff, 0xffff, 0xffff, 0xffff, 0xffff, 0xffff, 0xffff, 0xffff, 0xffff, 0xffff, 0xffff, 0xffff, 0xffff, 0xffff, 0xffff, 0xffff, 0xffff, 0xffff, 0xffff, 0xffff, 0xffff, 0xffff, 0xffff, 0xffff, 0x9386, 0x8925, 0x8925, 0x8925, 0x8925, 0x8925, 0x8925, 0x8925, 0x8925, 0x8925, 0x8925, 0x8925, 0x8925, 0xd496, 0xffff, 0xffff, 0xffff, 0xffff, 0xffff, 0xffff, 0xffff, 0xffff, 0xffff, 0xffff, 0xffff, 0xffff, 0xffff, 0xffff, 0xffff, 0xffff, 0xffff, 0xffff, 0xffff, 0xffff, 0xffff, 0xffff,
  0xffff, 0xffff, 0xffff, 0xffff, 0xffff, 0xffff, 0xffff, 0xffff, 0xffff, 0xffff, 0xffff, 0xffff, 0xffff, 0xffff, 0xffff, 0xffff, 0xffff, 0xffff, 0xffff, 0xffff, 0xffff, 0xffff, 0xffff, 0xffff, 0x937e, 0x8925, 0x8925, 0x8925, 0x8925, 0x8925, 0x8925, 0x8925, 0x8925, 0x8925, 0x8925, 0x8925, 0x8925, 0xd496, 0xffff, 0xffff, 0xffff, 0xffff, 0xffff, 0xffff, 0xffff, 0xffff, 0xffff, 0xffff, 0xffff, 0xffff, 0xffff, 0xffff, 0xffff, 0xffff, 0xffff, 0xffff, 0xffff, 0xffff, 0xffff, 0xffff,
  0xffff, 0xffff, 0xffff, 0xffff, 0xffff, 0xffff, 0xffff, 0xffff, 0xffff, 0xffff, 0xffff, 0xffff, 0xffff, 0xffff, 0xffff, 0xffff, 0xffff, 0xffff, 0xffff, 0xffff, 0xffff, 0xffff, 0xffff, 0xffff, 0x9386, 0x8925, 0x8925, 0x8925, 0x8925, 0x8925, 0x8925, 0x8925, 0x8925, 0x8925, 0x8925, 0x8925, 0x8925, 0xd496, 0xffff, 0xffff, 0xffff, 0xffff, 0xffff, 0xffff, 0xffff, 0xffff, 0xffff, 0xffff, 0xffff, 0xffff, 0xffff, 0xffff, 0xffff, 0xffff, 0xffff, 0xffff, 0xffff, 0xffff, 0xffff, 0xffff,
  0xffff, 0xffff, 0xffff, 0xffff, 0xffff, 0xffff, 0xffff, 0xffff, 0xffff, 0xffff, 0xffff, 0xffff, 0xffff, 0xffff, 0xffff, 0xffff, 0xffff, 0xffff, 0xffff, 0xffff, 0xffff, 0xffff, 0xffff, 0xffff, 0x9386, 0x8a2d, 0x8925, 0x8925, 0x8925, 0x8925, 0x8925, 0x8925, 0x8925, 0x8925, 0x8925, 0x8925, 0x8925, 0xd496, 0xffff, 0xffff, 0xffff, 0xffff, 0xffff, 0xffff, 0xffff, 0xffff, 0xffff, 0xffff, 0xffff, 0xffff, 0xffff, 0xffff, 0xffff, 0xffff, 0xffff, 0xffff, 0xffff, 0xffff, 0xffff, 0xffff,
  0xffff, 0xffff, 0xffff, 0xffff, 0xffff, 0xffff, 0xffff, 0xffff, 0xffff, 0xffff, 0xffff, 0xffff, 0xffff, 0xffff, 0xffff, 0xffff, 0xffff, 0xffff, 0xffff, 0xffff, 0xffff, 0xffff, 0xffff, 0xffff, 0x17b7, 0x516e, 0xcc45, 0x8925, 0x8925, 0x8925, 0x8925, 0x8925, 0x8925, 0x8925, 0x8925, 0x8925, 0x8925, 0xd496, 0xffff, 0xffff, 0xffff, 0xffff, 0xffff, 0xffff, 0xffff, 0xffff, 0xffff, 0xffff, 0xffff, 0xffff, 0xffff, 0xffff, 0xffff, 0xffff, 0xffff, 0xffff, 0xffff, 0xffff, 0xffff, 0xffff,
  0xffff, 0xffff, 0xffff, 0xffff, 0xffff, 0xffff, 0xffff, 0xffff, 0xffff, 0xffff, 0xffff, 0xffff, 0xffff, 0xffff, 0xffff, 0xffff, 0xffff, 0xffff, 0xffff, 0xffff, 0xffff, 0xffff, 0xffff, 0xffff, 0x7bd7, 0xf6a6, 0x2f5e, 0xaa2d, 0x8925, 0x8925, 0x8925, 0x8925, 0x8925, 0x8925, 0x8925, 0x8a2d, 0xab35, 0xd59e, 0xffff, 0xffff, 0xffff, 0xffff, 0xffff, 0xffff, 0xffff, 0xffff, 0xffff, 0xffff, 0xffff, 0xffff, 0xffff, 0xffff, 0xffff, 0xffff, 0xffff, 0xffff, 0xffff, 0xffff, 0xffff, 0xffff,
  0xffff, 0xffff, 0xffff, 0xffff, 0xffff, 0xffff, 0xffff, 0xffff, 0xffff, 0xffff, 0xffff, 0xffff, 0xffff, 0xffff, 0xffff, 0xffff, 0xffff, 0xffff, 0xffff, 0xffff, 0xffff, 0xffff, 0xffff, 0xffff, 0xbde7, 0x7acf, 0xd596, 0x506e, 0xcc3d, 0x8925, 0x8925, 0x8925, 0x8925, 0x8925, 0x8925, 0xed4d, 0x9386, 0x5ac7, 0xffff, 0xffff, 0xffff, 0xffff, 0xffff, 0xffff, 0xffff, 0xffff, 0xffff, 0xffff, 0xffff, 0xffff, 0xffff, 0xffff, 0xffff, 0xffff, 0xffff, 0xffff, 0xffff, 0xffff, 0xffff, 0xffff,
  0xffff, 0xffff, 0xffff, 0xffff, 0xffff, 0xffff, 0xffff, 0xffff, 0xffff, 0xffff, 0xffff, 0xffff, 0xffff, 0xffff, 0xffff, 0xffff, 0xffff, 0xffff, 0xffff, 0xffff, 0xffff, 0xffff, 0xffff, 0xffff, 0xdef7, 0xbde7, 0x59c7, 0xf69e, 0x506e, 0xed4d, 0xed4d, 0xed4d, 0xed4d, 0xed4d, 0xed4d, 0x927e, 0x59c7, 0xbde7, 0xffff, 0xffff, 0xffff, 0xffff, 0xffff, 0xffff, 0xffff, 0xffff, 0xffff, 0xffff, 0xffff, 0xffff, 0xffff, 0xffff, 0xffff, 0xffff, 0xffff, 0xffff, 0xffff, 0xffff, 0xffff, 0xffff,
  0xffff, 0xffff, 0xffff, 0xffff, 0xffff, 0xffff, 0xffff, 0xffff, 0xffff, 0xffff, 0xffff, 0xffff, 0xffff, 0xffff, 0xffff, 0xffff, 0xffff, 0xffff, 0xffff, 0xffff, 0xffff, 0xffff, 0xffff, 0xffff, 0xffff, 0xfff7, 0xddef, 0xbce7, 0x7bd7, 0x5ac7, 0x5ac7, 0x5ac7, 0x5ac7, 0x5ac7, 0x5ac7, 0x9bd7, 0xddef, 0xfff7, 0xffff, 0xffff, 0xffff, 0xffff, 0xffff, 0xffff, 0xffff, 0xffff, 0xffff, 0xffff, 0xffff, 0xffff, 0xffff, 0xffff, 0xffff, 0xffff, 0xffff, 0xffff, 0xffff, 0xffff, 0xffff, 0xffff,
  0xffff, 0xffff, 0xffff, 0xffff, 0xffff, 0xffff, 0xffff, 0xffff, 0xffff, 0xffff, 0xffff, 0xffff, 0xffff, 0xffff, 0xffff, 0xffff, 0xffff, 0xffff, 0xffff, 0xffff, 0xffff, 0xffff, 0xffff, 0xffff, 0xffff, 0xffff, 0xffff, 0xffff, 0xffff, 0xffff, 0xffff, 0xffff, 0xffff, 0xffff, 0xffff, 0xffff, 0xffff, 0xffff, 0xffff, 0xffff, 0xffff, 0xffff, 0xffff, 0xffff, 0xffff, 0xffff, 0xffff, 0xffff, 0xffff, 0xffff, 0xffff, 0xffff, 0xffff, 0xffff, 0xffff, 0xffff, 0xffff, 0xffff, 0xffff, 0xffff,
  0xffff, 0xffff, 0xffff, 0xffff, 0xffff, 0xffff, 0xffff, 0xffff, 0xffff, 0xffff, 0xffff, 0xffff, 0xffff, 0xffff, 0xffff, 0xffff, 0xffff, 0xffff, 0xffff, 0xffff, 0xffff, 0xffff, 0xffff, 0xffff, 0xffff, 0xffff, 0xffff, 0xffff, 0xffff, 0xffff, 0xffff, 0xffff, 0xffff, 0xffff, 0xffff, 0xffff, 0xffff, 0xffff, 0xffff, 0xffff, 0xffff, 0xffff, 0xffff, 0xffff, 0xffff, 0xffff, 0xffff, 0xffff, 0xffff, 0xffff, 0xffff, 0xffff, 0xffff, 0xffff, 0xffff, 0xffff, 0xffff, 0xffff, 0xffff, 0xffff,
  0xffff, 0xffff, 0xffff, 0xffff, 0xffff, 0xffff, 0xffff, 0xffff, 0xffff, 0xffff, 0xffff, 0xffff, 0xffff, 0xffff, 0xffff, 0xffff, 0xffff, 0xffff, 0xffff, 0xffff, 0xffff, 0xffff, 0xffff, 0xffff, 0xffff, 0xffff, 0xffff, 0xffff, 0xffff, 0xffff, 0xffff, 0xffff, 0xffff, 0xffff, 0xffff, 0xffff, 0xffff, 0xffff, 0xffff, 0xffff, 0xffff, 0xffff, 0xffff, 0xffff, 0xffff, 0xffff, 0xffff, 0xffff, 0xffff, 0xffff, 0xffff, 0xffff, 0xffff, 0xffff, 0xffff, 0xffff, 0xffff, 0xffff, 0xffff, 0xffff,
  0xffff, 0xffff, 0xffff, 0xffff, 0xffff, 0xffff, 0xffff, 0xffff, 0xffff, 0xffff, 0xffff, 0xffff, 0xffff, 0xffff, 0xffff, 0xffff, 0xffff, 0xffff, 0xffff, 0xffff, 0xffff, 0xffff, 0xffff, 0xffff, 0xffff, 0xffff, 0xffff, 0xffff, 0xffff, 0xffff, 0xffff, 0xffff, 0xffff, 0xffff, 0xffff, 0xffff, 0xffff, 0xffff, 0xffff, 0xffff, 0xffff, 0xffff, 0xffff, 0xffff, 0xffff, 0xffff, 0xffff, 0xffff, 0xffff, 0xffff, 0xffff, 0xffff, 0xffff, 0xffff, 0xffff, 0xffff, 0xffff, 0xffff, 0xffff, 0xffff,
  0xffff, 0xffff, 0xffff, 0xffff, 0xffff, 0xffff, 0xffff, 0xffff, 0xffff, 0xffff, 0xffff, 0xffff, 0xffff, 0xffff, 0xffff, 0xffff, 0xffff, 0xffff, 0xffff, 0xffff, 0xffff, 0xffff, 0xffff, 0xffff, 0xffff, 0xffff, 0xffff, 0xffff, 0xffff, 0xffff, 0xffff, 0xffff, 0xffff, 0xffff, 0xffff, 0xffff, 0xffff, 0xffff, 0xffff, 0xffff, 0xffff, 0xffff, 0xffff, 0xffff, 0xffff, 0xffff, 0xffff, 0xffff, 0xffff, 0xffff, 0xffff, 0xffff, 0xffff, 0xffff, 0xffff, 0xffff, 0xffff, 0xffff, 0xffff, 0xffff,
  0xffff, 0xffff, 0xffff, 0xffff, 0xffff, 0xffff, 0xffff, 0xffff, 0xffff, 0xffff, 0xffff, 0xffff, 0xffff, 0xffff, 0xffff, 0xffff, 0xffff, 0xffff, 0xffff, 0xffff, 0xffff, 0xffff, 0xffff, 0xffff, 0xffff, 0xffff, 0xffff, 0xffff, 0xffff, 0xffff, 0xffff, 0xffff, 0xffff, 0xffff, 0xffff, 0xffff, 0xffff, 0xffff, 0xffff, 0xffff, 0xffff, 0xffff, 0xffff, 0xffff, 0xffff, 0xffff, 0xffff, 0xffff, 0xffff, 0xffff, 0xffff, 0xffff, 0xffff, 0xffff, 0xffff, 0xffff, 0xffff, 0xffff, 0xffff, 0xffff,
  0xffff, 0xffff, 0xffff, 0xffff, 0xffff, 0xffff, 0xffff, 0xffff, 0xffff, 0xffff, 0xffff, 0xffff, 0xffff, 0xffff, 0xffff, 0xffff, 0xffff, 0xffff, 0xffff, 0xffff, 0xffff, 0xffff, 0xffff, 0xffff, 0xffff, 0xffff, 0xffff, 0xffff, 0xffff, 0xffff, 0xffff, 0xffff, 0xffff, 0xffff, 0xffff, 0xffff, 0xffff, 0xffff, 0xffff, 0xffff, 0xffff, 0xffff, 0xffff, 0xffff, 0xffff, 0xffff, 0xffff, 0xffff, 0xffff, 0xffff, 0xffff, 0xffff, 0xffff, 0xffff, 0xffff, 0xffff, 0xffff, 0xffff, 0xffff, 0xffff,
  0xffff, 0xffff, 0xffff, 0xffff, 0xffff, 0xffff, 0xffff, 0xffff, 0xffff, 0xffff, 0xffff, 0xffff, 0xffff, 0xffff, 0xffff, 0xffff, 0xffff, 0xffff, 0xffff, 0xffff, 0xffff, 0xffff, 0xffff, 0xffff, 0xffff, 0xffff, 0xffff, 0xffff, 0xffff, 0xffff, 0xffff, 0xffff, 0xffff, 0xffff, 0xffff, 0xffff, 0xffff, 0xffff, 0xffff, 0xffff, 0xffff, 0xffff, 0xffff, 0xffff, 0xffff, 0xffff, 0xffff, 0xffff, 0xffff, 0xffff, 0xffff, 0xffff, 0xffff, 0xffff, 0xffff, 0xffff, 0xffff, 0xffff, 0xffff, 0xffff,
  0xffff, 0xffff, 0xffff, 0xffff, 0xffff, 0xffff, 0xffff, 0xffff, 0xffff, 0xffff, 0xffff, 0xffff, 0xffff, 0xffff, 0xffff, 0xffff, 0xffff, 0xffff, 0xffff, 0xffff, 0xffff, 0xffff, 0xffff, 0xffff, 0xffff, 0xffff, 0xffff, 0xffff, 0xffff, 0xffff, 0xffff, 0xffff, 0xffff, 0xffff, 0xffff, 0xffff, 0xffff, 0xffff, 0xffff, 0xffff, 0xffff, 0xffff, 0xffff, 0xffff, 0xffff, 0xffff, 0xffff, 0xffff, 0xffff, 0xffff, 0xffff, 0xffff, 0xffff, 0xffff, 0xffff, 0xffff, 0xffff, 0xffff, 0xffff, 0xffff,
  0xffff, 0xffff, 0xffff, 0xffff, 0xffff, 0xffff, 0xffff, 0xffff, 0xffff, 0xffff, 0xffff, 0xffff, 0xffff, 0xffff, 0xffff, 0xffff, 0xffff, 0xffff, 0xffff, 0xffff, 0xffff, 0xffff, 0xffff, 0xffff, 0xffff, 0xffff, 0xffff, 0xffff, 0xffff, 0xffff, 0xffff, 0xffff, 0xffff, 0xffff, 0xffff, 0xffff, 0xffff, 0xffff, 0xffff, 0xffff, 0xffff, 0xffff, 0xffff, 0xffff, 0xffff, 0xffff, 0xffff, 0xffff, 0xffff, 0xffff, 0xffff, 0xffff, 0xffff, 0xffff, 0xffff, 0xffff, 0xffff, 0xffff, 0xffff, 0xffff,
  0xffff, 0xffff, 0xffff, 0xffff, 0xffff, 0xffff, 0xffff, 0xffff, 0xffff, 0xffff, 0xffff, 0xffff, 0xffff, 0xffff, 0xffff, 0xffff, 0xffff, 0xffff, 0xffff, 0xffff, 0xffff, 0xffff, 0xffff, 0xffff, 0xffff, 0xffff, 0xffff, 0xffff, 0xffff, 0xffff, 0xffff, 0xffff, 0xffff, 0xffff, 0xffff, 0xffff, 0xffff, 0xffff, 0xffff, 0xffff, 0xffff, 0xffff, 0xffff, 0xffff, 0xffff, 0xffff, 0xffff, 0xffff, 0xffff, 0xffff, 0xffff, 0xffff, 0xffff, 0xffff, 0xffff, 0xffff, 0xffff, 0xffff, 0xffff, 0xffff,
  0xffff, 0xffff, 0xffff, 0xffff, 0xffff, 0xffff, 0xffff, 0xffff, 0xffff, 0xffff, 0xffff, 0xffff, 0xffff, 0xffff, 0xffff, 0xffff, 0xffff, 0xffff, 0xffff, 0xffff, 0xffff, 0xffff, 0xffff, 0xffff, 0xffff, 0xffff, 0xffff, 0xffff, 0xffff, 0xffff, 0xffff, 0xffff, 0xffff, 0xffff, 0xffff, 0xffff, 0xffff, 0xffff, 0xffff, 0xffff, 0xffff, 0xffff, 0xffff, 0xffff, 0xffff, 0xffff, 0xffff, 0xffff, 0xffff, 0xffff, 0xffff, 0xffff, 0xffff, 0xffff, 0xffff, 0xffff, 0xffff, 0xffff, 0xffff, 0xffff,
  0xffff, 0xffff, 0xffff, 0xffff, 0xffff, 0xffff, 0xffff, 0xffff, 0xffff, 0xffff, 0xffff, 0xffff, 0xffff, 0xffff, 0xffff, 0xffff, 0xffff, 0xffff, 0xffff, 0xffff, 0xffff, 0xffff, 0xffff, 0xffff, 0xffff, 0xffff, 0xffff, 0xffff, 0xffff, 0xffff, 0xffff, 0xffff, 0xffff, 0xffff, 0xffff, 0xffff, 0xffff, 0xffff, 0xffff, 0xffff, 0xffff, 0xffff, 0xffff, 0xffff, 0xffff, 0xffff, 0xffff, 0xffff, 0xffff, 0xffff, 0xffff, 0xffff, 0xffff, 0xffff, 0xffff, 0xffff, 0xffff, 0xffff, 0xffff, 0xffff,
  0xffff, 0xffff, 0xffff, 0xffff, 0xffff, 0xffff, 0xffff, 0xffff, 0xffff, 0xffff, 0xffff, 0xffff, 0xffff, 0xffff, 0xffff, 0xffff, 0xffff, 0xffff, 0xffff, 0xffff, 0xffff, 0xffff, 0xffff, 0xffff, 0xffff, 0xffff, 0xffff, 0xffff, 0xffff, 0xffff, 0xffff, 0xffff, 0xffff, 0xffff, 0xffff, 0xffff, 0xffff, 0xffff, 0xffff, 0xffff, 0xffff, 0xffff, 0xffff, 0xffff, 0xffff, 0xffff, 0xffff, 0xffff, 0xffff, 0xffff, 0xffff, 0xffff, 0xffff, 0xffff, 0xffff, 0xffff, 0xffff, 0xffff, 0xffff, 0xffff
};
// array size is 7200
static const uint16_t img2[][60*60/2]  = {
  0xffff, 0xffff, 0xffff, 0xffff, 0xffff, 0xffff, 0xffff, 0xffff, 0xffff, 0xffff, 0xffff, 0xffff, 0xffff, 0xffff, 0xffff, 0xffff, 0xffff, 0xffff, 0xffff, 0xffff, 0xffff, 0xffff, 0xffff, 0xffff, 0xffff, 0xffff, 0xffff, 0xffff, 0xffff, 0xffff, 0xffff, 0xffff, 0xffff, 0xffff, 0xffff, 0xffff, 0xffff, 0xffff, 0xffff, 0xffff, 0xffff, 0xffff, 0xffff, 0xffff, 0xffff, 0xffff, 0xffff, 0xffff, 0xffff, 0xffff, 0xffff, 0xffff, 0xffff, 0xffff, 0xffff, 0xffff, 0xffff, 0xffff, 0xffff, 0xffff,
  0xffff, 0xffff, 0xffff, 0xffff, 0xffff, 0xffff, 0xffff, 0xffff, 0xffff, 0xffff, 0xffff, 0xffff, 0xffff, 0xffff, 0xffff, 0xffff, 0xffff, 0xffff, 0xffff, 0xffff, 0xffff, 0xffff, 0xffff, 0xffff, 0xffff, 0xffff, 0xffff, 0xffff, 0xffff, 0xffff, 0xffff, 0xffff, 0xffff, 0xffff, 0xffff, 0xffff, 0xffff, 0xffff, 0xffff, 0xffff, 0xffff, 0xffff, 0xffff, 0xffff, 0xffff, 0xffff, 0xffff, 0xffff, 0xffff, 0xffff, 0xffff, 0xffff, 0xffff, 0xffff, 0xffff, 0xffff, 0xffff, 0xffff, 0xffff, 0xffff,
  0xffff, 0xffff, 0xffff, 0xffff, 0xffff, 0xffff, 0xffff, 0xffff, 0xffff, 0xffff, 0xffff, 0xffff, 0xffff, 0xffff, 0xffff, 0xffff, 0xffff, 0xffff, 0xffff, 0xffff, 0xffff, 0xffff, 0xffff, 0xffff, 0xffff, 0xffff, 0xffff, 0xffff, 0xffff, 0xffff, 0xffff, 0xffff, 0xffff, 0xffff, 0xffff, 0xffff, 0xffff, 0xffff, 0xffff, 0xffff, 0xffff, 0xffff, 0xffff, 0xffff, 0xffff, 0xffff, 0xffff, 0xffff, 0xffff, 0xffff, 0xffff, 0xffff, 0xffff, 0xffff, 0xffff, 0xffff, 0xffff, 0xffff, 0xffff, 0xffff,
  0xffff, 0xffff, 0xffff, 0xffff, 0xffff, 0xffff, 0xffff, 0xffff, 0xffff, 0xffff, 0xffff, 0xffff, 0xffff, 0xffff, 0xffff, 0xffff, 0xffff, 0xffff, 0xffff, 0xffff, 0xffff, 0xffff, 0xffff, 0xffff, 0xffff, 0xffff, 0xffff, 0xffff, 0xffff, 0xffff, 0xffff, 0xffff, 0xffff, 0xffff, 0xffff, 0xffff, 0xffff, 0xffff, 0xffff, 0xffff, 0xffff, 0xffff, 0xffff, 0xffff, 0xffff, 0xffff, 0xffff, 0xffff, 0xffff, 0xffff, 0xffff, 0xffff, 0xffff, 0xffff, 0xffff, 0xffff, 0xffff, 0xffff, 0xffff, 0xffff,
  0xffff, 0xffff, 0xffff, 0xffff, 0xffff, 0xffff, 0xffff, 0xffff, 0xffff, 0xffff, 0xffff, 0xffff, 0xffff, 0xffff, 0xffff, 0xffff, 0xffff, 0xffff, 0xffff, 0xffff, 0xffff, 0xffff, 0xffff, 0xffff, 0xffff, 0xffff, 0xffff, 0xffff, 0xffff, 0xffff, 0xffff, 0xffff, 0xffff, 0xffff, 0xffff, 0xffff, 0xffff, 0xffff, 0xffff, 0xffff, 0xffff, 0xffff, 0xffff, 0xffff, 0xffff, 0xffff, 0xffff, 0xffff, 0xffff, 0xffff, 0xffff, 0xffff, 0xffff, 0xffff, 0xffff, 0xffff, 0xffff, 0xffff, 0xffff, 0xffff,
  0xffff, 0xffff, 0xffff, 0xffff, 0xffff, 0xffff, 0xffff, 0xffff, 0xffff, 0xffff, 0xffff, 0xffff, 0xffff, 0xffff, 0xffff, 0xffff, 0xffff, 0xffff, 0xffff, 0xffff, 0xffff, 0xffff, 0xffff, 0xffff, 0xffff, 0xffff, 0xffff, 0xffff, 0xffff, 0xffff, 0xffff, 0xffff, 0xffff, 0xffff, 0xffff, 0xffff, 0xffff, 0xffff, 0xffff, 0xffff, 0xffff, 0xffff, 0xffff, 0xffff, 0xffff, 0xffff, 0xffff, 0xffff, 0xffff, 0xffff, 0xffff, 0xffff, 0xffff, 0xffff, 0xffff, 0xffff, 0xffff, 0xffff, 0xffff, 0xffff,
  0xffff, 0xffff, 0xffff, 0xffff, 0xffff, 0xffff, 0xffff, 0xffff, 0xffff, 0xffff, 0xffff, 0xffff, 0xffff, 0xffff, 0xffff, 0xffff, 0xffff, 0xffff, 0xffff, 0xffff, 0xffff, 0xffff, 0xffff, 0xffff, 0xffff, 0xffff, 0xffff, 0xffff, 0xffff, 0xffff, 0xffff, 0xffff, 0xffff, 0xffff, 0xffff, 0xffff, 0xffff, 0xffff, 0xffff, 0xffff, 0xffff, 0xffff, 0xffff, 0xffff, 0xffff, 0xffff, 0xffff, 0xffff, 0xffff, 0xffff, 0xffff, 0xffff, 0xffff, 0xffff, 0xffff, 0xffff, 0xffff, 0xffff, 0xffff, 0xffff,
  0xffff, 0xffff, 0xffff, 0xffff, 0xffff, 0xffff, 0xffff, 0xffff, 0xffff, 0xffff, 0xffff, 0xffff, 0xffff, 0xffff, 0xffff, 0xffff, 0xffff, 0xffff, 0xffff, 0xffff, 0xffff, 0xffff, 0xffff, 0xffff, 0xffff, 0xffff, 0xffff, 0xffff, 0xffff, 0xffff, 0xffff, 0xffff, 0xffff, 0xffff, 0xffff, 0xffff, 0xffff, 0xffff, 0xffff, 0xffff, 0xffff, 0xffff, 0xffff, 0xffff, 0xffff, 0xffff, 0xffff, 0xffff, 0xffff, 0xffff, 0xffff, 0xffff, 0xffff, 0xffff, 0xffff, 0xffff, 0xffff, 0xffff, 0xffff, 0xffff,
  0xffff, 0xffff, 0xffff, 0xffff, 0xffff, 0xffff, 0xffff, 0xffff, 0xffff, 0xffff, 0xffff, 0xffff, 0xffff, 0xffff, 0xffff, 0xffff, 0xffff, 0xffff, 0xffff, 0xffff, 0xffff, 0xffff, 0xffff, 0xffff, 0xffff, 0xffff, 0xffff, 0xffff, 0xffff, 0xffff, 0xffff, 0xffff, 0xffff, 0xffff, 0xffff, 0xffff, 0xffff, 0xffff, 0xffff, 0xffff, 0xffff, 0xffff, 0xffff, 0xffff, 0xffff, 0xffff, 0xffff, 0xffff, 0xffff, 0xffff, 0xffff, 0xffff, 0xffff, 0xffff, 0xffff, 0xffff, 0xffff, 0xffff, 0xffff, 0xffff,
  0xffff, 0xffff, 0xffff, 0xffff, 0xffff, 0xffff, 0xffff, 0xffff, 0xffff, 0xffff, 0xffff, 0xffff, 0xffff, 0xffff, 0xffff, 0xffff, 0xffff, 0xffff, 0xffff, 0xffff, 0xffff, 0xffff, 0xffff, 0xffff, 0xffff, 0xffff, 0xffff, 0xffff, 0xffff, 0xffff, 0xffff, 0xffff, 0xffff, 0xffff, 0xffff, 0xffff, 0xffff, 0xffff, 0xffff, 0xffff, 0xffff, 0xffff, 0xffff, 0xffff, 0xffff, 0xffff, 0xffff, 0xffff, 0xffff, 0xffff, 0xffff, 0xffff, 0xffff, 0xffff, 0xffff, 0xffff, 0xffff, 0xffff, 0xffff, 0xffff,
  0xffff, 0xffff, 0xffff, 0xffff, 0xffff, 0xffff, 0xffff, 0xffff, 0xffff, 0xffff, 0xffff, 0xffff, 0xffff, 0xffff, 0xffff, 0xffff, 0xffff, 0xffff, 0xffff, 0xffff, 0xffff, 0xffff, 0xffff, 0xffff, 0xffff, 0xffff, 0xffff, 0xffff, 0xffff, 0xffff, 0xffff, 0xffff, 0xffff, 0xffff, 0xffff, 0xffff, 0xffff, 0xffff, 0xffff, 0xffff, 0xffff, 0xffff, 0xffff, 0xffff, 0xffff, 0xffff, 0xffff, 0xffff, 0xffff, 0xffff, 0xffff, 0xffff, 0xffff, 0xffff, 0xffff, 0xffff, 0xffff, 0xffff, 0xffff, 0xffff,
  0xffff, 0xffff, 0xffff, 0xffff, 0xffff, 0xffff, 0xffff, 0xffff, 0xffff, 0xffff, 0xffff, 0xffff, 0xffff, 0xffff, 0xffff, 0xffff, 0xffff, 0xffff, 0xffff, 0xffff, 0xffff, 0xffff, 0xffff, 0xffff, 0xffff, 0xffff, 0xffff, 0xffff, 0xffff, 0xffff, 0xffff, 0xffff, 0xffff, 0xffff, 0xffff, 0xffff, 0xffff, 0xffff, 0xffff, 0xffff, 0xffff, 0xffff, 0xffff, 0xffff, 0xffff, 0xffff, 0xffff, 0xffff, 0xffff, 0xffff, 0xffff, 0xffff, 0xffff, 0xffff, 0xffff, 0xffff, 0xffff, 0xffff, 0xffff, 0xffff,
  0xffff, 0xffff, 0xffff, 0xffff, 0xffff, 0xffff, 0xffff, 0xffff, 0xffff, 0xffff, 0xffff, 0xffff, 0xffff, 0xffff, 0xffff, 0xffff, 0xffff, 0xffff, 0xffff, 0xffff, 0xffff, 0xffff, 0xffff, 0xffff, 0xffff, 0xffff, 0xffff, 0xffff, 0xffff, 0xffff, 0xffff, 0xffff, 0xffff, 0xffff, 0xffff, 0xffff, 0xffff, 0xffff, 0xffff, 0xffff, 0xffff, 0xffff, 0xffff, 0xffff, 0xffff, 0xffff, 0xffff, 0xffff, 0xffff, 0xffff, 0xffff, 0xffff, 0xffff, 0xffff, 0xffff, 0xffff, 0xffff, 0xffff, 0xffff, 0xffff,
  0xffff, 0xffff, 0xffff, 0xffff, 0xffff, 0xffff, 0xffff, 0xffff, 0xffff, 0xffff, 0xffff, 0xffff, 0xffff, 0xffff, 0xffff, 0xffff, 0xffff, 0xffff, 0xffff, 0xffff, 0xffff, 0xffff, 0xffff, 0xffff, 0xffff, 0xffff, 0xffff, 0xffff, 0xffff, 0xffff, 0xffff, 0xffff, 0xffff, 0xffff, 0xffff, 0xffff, 0xffff, 0xffff, 0xffff, 0xffff, 0xffff, 0xffff, 0xffff, 0xffff, 0xffff, 0xffff, 0xffff, 0xffff, 0xffff, 0xffff, 0xffff, 0xffff, 0xffff, 0xffff, 0xffff, 0xffff, 0xffff, 0xffff, 0xffff, 0xffff,
  0xffff, 0xffff, 0xffff, 0xffff, 0xffff, 0xffff, 0xffff, 0xffff, 0xffff, 0xffff, 0xffff, 0xffff, 0xffff, 0xffff, 0xffff, 0xffff, 0xffff, 0xffff, 0xffff, 0xffff, 0xffff, 0xffff, 0xffff, 0xffff, 0xffff, 0xffff, 0xffff, 0xffff, 0xffff, 0xffff, 0xffff, 0xffff, 0xffff, 0xffff, 0xffff, 0xffff, 0xffff, 0xffff, 0xffff, 0xffff, 0xffff, 0xffff, 0xffff, 0xffff, 0xffff, 0xffff, 0xffff, 0xffff, 0xffff, 0xffff, 0xffff, 0xffff, 0xffff, 0xffff, 0xffff, 0xffff, 0xffff, 0xffff, 0xffff, 0xffff,
  0xffff, 0xffff, 0xffff, 0xffff, 0xffff, 0xffff, 0xffff, 0xffff, 0xffff, 0xffff, 0xffff, 0xffff, 0xffff, 0xffff, 0xffff, 0xffff, 0xffff, 0xffff, 0xffff, 0xffff, 0xffff, 0xffff, 0xffff, 0xffff, 0xffff, 0xffff, 0xffff, 0xffff, 0xffff, 0xffff, 0xffff, 0xffff, 0xffff, 0xffff, 0xffff, 0xffff, 0xffff, 0xffff, 0xffff, 0xffff, 0xffff, 0xffff, 0xffff, 0xffff, 0xffff, 0xffff, 0xffff, 0xffff, 0xffff, 0xffff, 0xffff, 0xffff, 0xffff, 0xffff, 0xffff, 0xffff, 0xffff, 0xffff, 0xffff, 0xffff,
  0xffff, 0xffff, 0xffff, 0xffff, 0xffff, 0xffff, 0xffff, 0xffff, 0xffff, 0xffff, 0xffff, 0xffff, 0xffff, 0xffff, 0xffff, 0xffff, 0xffff, 0xffff, 0xffff, 0xffff, 0xffff, 0xffff, 0xffff, 0xffff, 0xffff, 0xffff, 0xffff, 0xffff, 0xffff, 0xffff, 0xffff, 0xffff, 0xffff, 0xffff, 0xffff, 0xffff, 0xffff, 0xffff, 0xffff, 0xffff, 0xffff, 0xffff, 0xffff, 0xffff, 0xffff, 0xffff, 0xffff, 0xffff, 0xffff, 0xffff, 0xffff, 0xffff, 0xffff, 0xffff, 0xffff, 0xffff, 0xffff, 0xffff, 0xffff, 0xffff,
  0xffff, 0xffff, 0xffff, 0xffff, 0xffff, 0xffff, 0xffff, 0xffff, 0xffff, 0xffff, 0xffff, 0xffff, 0xffff, 0xffff, 0xffff, 0xffff, 0xffff, 0xffff, 0xffff, 0xffff, 0xffff, 0xffff, 0xffff, 0xffff, 0xffff, 0xffff, 0xffff, 0xffff, 0xffff, 0xffff, 0xffff, 0xffff, 0xffff, 0xffff, 0xffff, 0xffff, 0xffff, 0xffff, 0xffff, 0xffff, 0xffff, 0xffff, 0xffff, 0xffff, 0xffff, 0xffff, 0xffff, 0xffff, 0xffff, 0xffff, 0xffff, 0xffff, 0xffff, 0xffff, 0xffff, 0xffff, 0xffff, 0xffff, 0xffff, 0xffff,
  0xffff, 0xffff, 0xffff, 0xffff, 0xffff, 0xffff, 0xffff, 0xffff, 0xffff, 0xffff, 0xffff, 0xffff, 0xffff, 0xffff, 0xffff, 0xffff, 0xffff, 0xffff, 0xffff, 0xffff, 0xffff, 0xffff, 0xffff, 0xffff, 0xffff, 0xffff, 0xffff, 0xffff, 0xffff, 0xffff, 0xffff, 0xffff, 0xffff, 0xffff, 0xffff, 0xffff, 0xffff, 0xffff, 0xffff, 0xffff, 0xffff, 0xffff, 0xffff, 0xffff, 0xffff, 0xffff, 0xffff, 0xffff, 0xffff, 0xffff, 0xffff, 0xffff, 0xffff, 0xffff, 0xffff, 0xffff, 0xffff, 0xffff, 0xffff, 0xffff,
  0xffff, 0xffff, 0xffff, 0xffff, 0xffff, 0xffff, 0xffff, 0xffff, 0xffff, 0xffff, 0xffff, 0xffff, 0xffff, 0xffff, 0xffff, 0xffff, 0xffff, 0xffff, 0xffff, 0xffff, 0xffff, 0xffff, 0xffff, 0xffff, 0xffff, 0xffff, 0xffff, 0xffff, 0xffff, 0xffff, 0xffff, 0xffff, 0xffff, 0xffff, 0xffff, 0xffff, 0xffff, 0xffff, 0xffff, 0xffff, 0xffff, 0xffff, 0xffff, 0xffff, 0xffff, 0xffff, 0xffff, 0xffff, 0xffff, 0xffff, 0xffff, 0xffff, 0xffff, 0xffff, 0xffff, 0xffff, 0xffff, 0xffff, 0xffff, 0xffff,
  0xffff, 0xffff, 0xffff, 0xffff, 0xffff, 0xffff, 0xffff, 0xffff, 0xffff, 0xffff, 0xffff, 0xffff, 0xffff, 0xffff, 0xffff, 0xffff, 0xffff, 0xffff, 0xffff, 0xffff, 0xffff, 0xffff, 0xffff, 0xffff, 0xffff, 0xffff, 0xffff, 0xffff, 0xffff, 0xffff, 0xffff, 0xffff, 0xffff, 0xffff, 0xffff, 0xffff, 0xffff, 0xffff, 0xffff, 0xffff, 0xffff, 0xffff, 0xffff, 0xffff, 0xffff, 0xffff, 0xffff, 0xffff, 0xffff, 0xffff, 0xffff, 0xffff, 0xffff, 0xffff, 0xffff, 0xffff, 0xffff, 0xffff, 0xffff, 0xffff,
  0xffff, 0xffff, 0xffff, 0xffff, 0xffff, 0xffff, 0xffff, 0xffff, 0xffff, 0xffff, 0xffff, 0xffff, 0xffff, 0xffff, 0xffff, 0xffff, 0xffff, 0xffff, 0xffff, 0xffff, 0xffff, 0xffff, 0xffff, 0xffff, 0xffff, 0xffff, 0xffff, 0xffff, 0xffff, 0xffff, 0xffff, 0xffff, 0xffff, 0xffff, 0xffff, 0xffff, 0xffff, 0xffff, 0xffff, 0xffff, 0xffff, 0xffff, 0xffff, 0xffff, 0xffff, 0xffff, 0xffff, 0xffff, 0xffff, 0xffff, 0xffff, 0xffff, 0xffff, 0xffff, 0xffff, 0xffff, 0xffff, 0xffff, 0xffff, 0xffff,
  0xffff, 0xffff, 0xffff, 0xffff, 0xffff, 0xffff, 0xffff, 0xffff, 0xffff, 0xffff, 0xffff, 0xffff, 0xffff, 0xffff, 0xffff, 0xffff, 0xffff, 0xffff, 0xffff, 0xffff, 0xffff, 0xffff, 0xffff, 0xffff, 0xffff, 0xffff, 0xffff, 0xffff, 0xffff, 0xffff, 0xffff, 0xffff, 0xffff, 0xffff, 0xffff, 0xffff, 0xffff, 0xffff, 0xffff, 0xffff, 0xffff, 0xffff, 0xffff, 0xffff, 0xffff, 0xffff, 0xffff, 0xffff, 0xffff, 0xffff, 0xffff, 0xffff, 0xffff, 0xffff, 0xffff, 0xffff, 0xffff, 0xffff, 0xffff, 0xffff,
  0xffff, 0xffff, 0xffff, 0xffff, 0xffff, 0xffff, 0xffff, 0xffff, 0xffff, 0xffff, 0xffff, 0xffff, 0xffff, 0xffff, 0xffff, 0xffff, 0xffff, 0xffff, 0xffff, 0xffff, 0xffff, 0xffff, 0xffff, 0xffff, 0xffff, 0xffff, 0xffff, 0xffff, 0xffff, 0xffff, 0xffff, 0xffff, 0xffff, 0xffff, 0xffff, 0xffff, 0xffff, 0xffff, 0xffff, 0xffff, 0xffff, 0xffff, 0xffff, 0xffff, 0xffff, 0xffff, 0xffff, 0xffff, 0xffff, 0xffff, 0xffff, 0xffff, 0xffff, 0xffff, 0xffff, 0xffff, 0xffff, 0xffff, 0xffff, 0xffff,
  0xffff, 0xffff, 0xffff, 0xffff, 0xffff, 0xffff, 0xffff, 0xffff, 0xffff, 0xffff, 0xffff, 0xffff, 0xffff, 0xffff, 0xffff, 0xffff, 0xffff, 0xffff, 0xffff, 0xffff, 0xffff, 0xffff, 0xffff, 0xffff, 0xffff, 0xffff, 0xffff, 0xffff, 0xffff, 0xffff, 0xffff, 0xffff, 0xffff, 0xffff, 0xffff, 0xffff, 0xffff, 0xffff, 0xffff, 0xffff, 0xffff, 0xffff, 0xffff, 0xffff, 0xffff, 0xffff, 0xffff, 0xffff, 0xffff, 0xffff, 0xffff, 0xffff, 0xffff, 0xffff, 0xffff, 0xffff, 0xffff, 0xffff, 0xffff, 0xffff,
  0xffff, 0xffff, 0xffff, 0xffff, 0xffff, 0xffff, 0xffff, 0xffff, 0xffff, 0xffff, 0xffff, 0xffff, 0xffff, 0xffff, 0xffff, 0xffff, 0xffff, 0xffff, 0xffff, 0xffff, 0xffff, 0xffff, 0xffff, 0xffff, 0xffff, 0xffff, 0xffff, 0xffff, 0xffff, 0xffff, 0xffff, 0xffff, 0xffff, 0xffff, 0xffff, 0xffff, 0xffff, 0xffff, 0xffff, 0xffff, 0xffff, 0xffff, 0xffff, 0xffff, 0xffff, 0xffff, 0xffff, 0xffff, 0xffff, 0xffff, 0xffff, 0xffff, 0xffff, 0xffff, 0xffff, 0xffff, 0xffff, 0xffff, 0xffff, 0xffff,
  0xffff, 0xffff, 0xffff, 0xffff, 0xffff, 0xffff, 0xffff, 0xffff, 0xffff, 0xffff, 0xffff, 0xffff, 0xffff, 0xffff, 0xffff, 0xffff, 0xffff, 0xffff, 0xffff, 0xffff, 0xffff, 0xffff, 0xffff, 0xffff, 0xffff, 0xffff, 0xffff, 0xffff, 0xffff, 0xffff, 0xffff, 0xffff, 0xffff, 0xffff, 0xffff, 0xffff, 0xffff, 0xffff, 0xffff, 0xffff, 0xffff, 0xffff, 0xffff, 0xffff, 0xffff, 0xffff, 0xffff, 0xffff, 0xffff, 0xffff, 0xffff, 0xffff, 0xffff, 0xffff, 0xffff, 0xffff, 0xffff, 0xffff, 0xffff, 0xffff,
  0xffff, 0xffff, 0xffff, 0xffff, 0xffff, 0xffff, 0xffff, 0xffff, 0xffff, 0xffff, 0xffff, 0xffff, 0xffff, 0xffff, 0xffff, 0xffff, 0xffff, 0xffff, 0xffff, 0xffff, 0xffff, 0xffff, 0xffff, 0xffff, 0xffff, 0xffff, 0xffff, 0xffff, 0xffff, 0xffff, 0xffff, 0xffff, 0xffff, 0xffff, 0xffff, 0xffff, 0xffff, 0xffff, 0xffff, 0xffff, 0xffff, 0xffff, 0xffff, 0xffff, 0xffff, 0xffff, 0xffff, 0xffff, 0xffff, 0xffff, 0xffff, 0xffff, 0xffff, 0xffff, 0xffff, 0xffff, 0xffff, 0xffff, 0xffff, 0xffff,
  0xffff, 0xffff, 0xffff, 0xffff, 0xffff, 0xffff, 0xffff, 0xffff, 0xffff, 0xffff, 0xffff, 0xffff, 0xffff, 0xffff, 0xffff, 0xffff, 0xffff, 0xffff, 0xffff, 0xffff, 0xffff, 0xffff, 0xffff, 0xffff, 0xffff, 0xffff, 0xffff, 0xffff, 0xffff, 0xffff, 0xffff, 0xffff, 0xffff, 0xffff, 0xffff, 0xffff, 0xffff, 0xffff, 0xffff, 0xffff, 0xffff, 0xffff, 0xffff, 0xffff, 0xffff, 0xffff, 0xffff, 0xffff, 0xffff, 0xffff, 0xffff, 0xffff, 0xffff, 0xffff, 0xffff, 0xffff, 0xffff, 0xffff, 0xffff, 0xffff,
  0xffff, 0xffff, 0xffff, 0xffff, 0xffff, 0xffff, 0xffff, 0xffff, 0xffff, 0xffff, 0xffff, 0xffff, 0xffff, 0xffff, 0xffff, 0xffff, 0xffff, 0xffff, 0xffff, 0xffff, 0xffff, 0xffff, 0xffff, 0xffff, 0xffff, 0xffff, 0xffff, 0xffff, 0xffff, 0xffff, 0xffff, 0xffff, 0xffff, 0xffff, 0xffff, 0xffff, 0xffff, 0xffff, 0xffff, 0xffff, 0xffff, 0xffff, 0xffff, 0xffff, 0xffff, 0xffff, 0xffff, 0xffff, 0xffff, 0xffff, 0xffff, 0xffff, 0xffff, 0xffff, 0xffff, 0xffff, 0xffff, 0xffff, 0xffff, 0xffff,
  0xffff, 0xffff, 0xffff, 0xffff, 0xffff, 0xffff, 0xffff, 0xffff, 0xffff, 0xffff, 0xffff, 0xffff, 0xffff, 0xffff, 0xffff, 0xffff, 0xffff, 0xffff, 0xffff, 0xffff, 0xffff, 0xffff, 0xffff, 0xffff, 0xffff, 0xffff, 0xffff, 0xffff, 0xffff, 0xffff, 0xffff, 0xffff, 0xffff, 0xffff, 0xffff, 0xffff, 0xffff, 0xffff, 0xffff, 0xffff, 0xffff, 0xffff, 0xffff, 0xffff, 0xffff, 0xffff, 0xffff, 0xffff, 0xffff, 0xffff, 0xffff, 0xffff, 0xffff, 0xffff, 0xffff, 0xffff, 0xffff, 0xffff, 0xffff, 0xffff,
  0xffff, 0xffff, 0xffff, 0xffff, 0xffff, 0xffff, 0xffff, 0xffff, 0xffff, 0xffff, 0xffff, 0xffff, 0xffff, 0xffff, 0xffff, 0xffff, 0xffff, 0xffff, 0xffff, 0xffff, 0xffff, 0xffff, 0xffff, 0xffff, 0xffff, 0xffff, 0xffff, 0xffff, 0xffff, 0xffff, 0xffff, 0xffff, 0xffff, 0xffff, 0xffff, 0xffff, 0xffff, 0xffff, 0xffff, 0xffff, 0xffff, 0xffff, 0xffff, 0xffff, 0xffff, 0xffff, 0xffff, 0xffff, 0xffff, 0xffff, 0xffff, 0xffff, 0xffff, 0xffff, 0xffff, 0xffff, 0xffff, 0xffff, 0xffff, 0xffff,
  0xffff, 0xffff, 0xffff, 0xffff, 0xffff, 0xffff, 0xffff, 0xffff, 0xffff, 0xffff, 0xffff, 0xffff, 0xffff, 0xffff, 0xffff, 0xffff, 0xffff, 0xffff, 0xffff, 0xffff, 0xffff, 0xffff, 0xffff, 0xffff, 0xffff, 0xffff, 0xffff, 0xffff, 0xffff, 0xffff, 0xffff, 0xffff, 0xffff, 0xffff, 0xffff, 0xdef7, 0xdeef, 0xfff7, 0xffff, 0xffff, 0xffff, 0xffff, 0xffff, 0xffff, 0xffff, 0xffff, 0xffff, 0xffff, 0xffff, 0xffff, 0xffff, 0xffff, 0xffff, 0xffff, 0xffff, 0xffff, 0xffff, 0xffff, 0xffff, 0xffff,
  0xffff, 0xffff, 0xffff, 0xffff, 0xffff, 0xffff, 0xffff, 0xffff, 0xffff, 0xffff, 0xffff, 0xffff, 0xffff, 0xffff, 0xffff, 0xffff, 0xffff, 0xffff, 0xffff, 0xffff, 0xffff, 0xffff, 0xffff, 0xffff, 0xffff, 0xffff, 0xffff, 0xffff, 0xffff, 0xffff, 0xffff, 0xffff, 0xffff, 0xffff, 0xffff, 0xdef7, 0xdeef, 0xdef7, 0xffff, 0xffff, 0xffff, 0xffff, 0xffff, 0xffff, 0xffff, 0xffff, 0xffff, 0xffff, 0xffff, 0xffff, 0xffff, 0xffff, 0xffff, 0xffff, 0xffff, 0xffff, 0xffff, 0xffff, 0xffff, 0xffff,
  0xffff, 0xffff, 0xffff, 0xffff, 0xffff, 0xffff, 0xffff, 0xffff, 0xffff, 0xffff, 0xffff, 0xffff, 0xffff, 0xffff, 0xffff, 0xffff, 0xffff, 0xffff, 0xffff, 0xffff, 0xffff, 0xffff, 0xffff, 0xffff, 0xffff, 0xffff, 0xffff, 0xffff, 0xffff, 0xffff, 0xffff, 0xffff, 0xffff, 0xffff, 0xffff, 0xffff, 0xdeef, 0xdff7, 0xffff, 0xffff, 0xffff, 0xffff, 0xffff, 0xffff, 0xffff, 0xffff, 0xffff, 0xffff, 0xffff, 0xffff, 0xffff, 0xffff, 0xffff, 0xffff, 0xffff, 0xffff, 0xffff, 0xffff, 0xffff, 0xffff,
  0xffff, 0xffff, 0xffff, 0xffff, 0xffff, 0xffff, 0xffff, 0xffff, 0xffff, 0xffff, 0xffff, 0xffff, 0xffff, 0xffff, 0xffff, 0xffff, 0xffff, 0xffff, 0xffff, 0xffff, 0xffff, 0xffff, 0xffff, 0xffff, 0xffff, 0xffff, 0xffff, 0xffff, 0xffff, 0xffff, 0xffff, 0xffff, 0xffff, 0xffff, 0xffff, 0xffff, 0xdef7, 0xffff, 0xffff, 0xffff, 0xffff, 0xffff, 0xffff, 0xffff, 0xffff, 0xffff, 0xffff, 0xffff, 0xffff, 0xffff, 0xffff, 0xffff, 0xffff, 0xffff, 0xffff, 0xffff, 0xffff, 0xffff, 0xffff, 0xffff,
  0xffff, 0xffff, 0xffff, 0xffff, 0xffff, 0xffff, 0xffff, 0xffff, 0xffff, 0xffff, 0xffff, 0xffff, 0xffff, 0xffff, 0xffff, 0xffff, 0xffff, 0xffff, 0xffff, 0xffff, 0xffff, 0xffff, 0xffff, 0xffff, 0xffff, 0xffff, 0xffff, 0xffff, 0xffff, 0xffff, 0xffff, 0xffff, 0xffff, 0xffff, 0xffff, 0xffff, 0xffff, 0xffff, 0xffff, 0xffff, 0xffff, 0xffff, 0xffff, 0xffff, 0xffff, 0xffff, 0xffff, 0xffff, 0xffff, 0xffff, 0xffff, 0xffff, 0xffff, 0xffff, 0xffff, 0xffff, 0xffff, 0xffff, 0xffff, 0xffff,
  0xffff, 0xffff, 0xffff, 0xffff, 0xffff, 0xffff, 0xffff, 0xffff, 0xffff, 0xffff, 0xffff, 0xffff, 0xffff, 0xffff, 0xffff, 0xffff, 0xffff, 0xffff, 0xffff, 0xffff, 0xffff, 0xffff, 0xffff, 0xffff, 0xffff, 0xffff, 0xffff, 0xffff, 0xffff, 0xffff, 0xffff, 0xffff, 0xffff, 0xffff, 0xffff, 0xffff, 0xffff, 0xffff, 0xffff, 0xffff, 0xffff, 0xffff, 0xffff, 0xffff, 0xffff, 0xffff, 0xffff, 0xffff, 0xffff, 0xffff, 0xffff, 0xffff, 0xffff, 0xffff, 0xffff, 0xffff, 0xffff, 0xffff, 0xffff, 0xffff,
  0xffff, 0xffff, 0xffff, 0xffff, 0xffff, 0xffff, 0xffff, 0xffff, 0xffff, 0xffff, 0xffff, 0xffff, 0xffff, 0xffff, 0xffff, 0xffff, 0xffff, 0xffff, 0xffff, 0xffff, 0xffff, 0xffff, 0xffff, 0xffff, 0xffff, 0xffff, 0xffff, 0xffff, 0xffff, 0xffff, 0xffff, 0xffff, 0xffff, 0xffff, 0xffff, 0xffff, 0xffff, 0xffff, 0xffff, 0xffff, 0xffff, 0xffff, 0xffff, 0xffff, 0xffff, 0xffff, 0xffff, 0xffff, 0xffff, 0xffff, 0xffff, 0xffff, 0xffff, 0xffff, 0xffff, 0xffff, 0xffff, 0xffff, 0xffff, 0xffff,
  0xffff, 0xffff, 0xffff, 0xffff, 0xffff, 0xffff, 0xffff, 0xffff, 0xffff, 0xffff, 0xffff, 0xffff, 0xffff, 0xffff, 0xffff, 0xffff, 0xffff, 0xffff, 0xffff, 0xffff, 0xffff, 0xffff, 0xffff, 0xffff, 0xffff, 0xffff, 0xffff, 0xffff, 0xffff, 0xffff, 0xffff, 0xffff, 0xffff, 0xffff, 0xffff, 0xffff, 0xffff, 0xffff, 0xffff, 0xffff, 0xffff, 0xffff, 0xffff, 0xffff, 0xffff, 0xffff, 0xffff, 0xffff, 0xffff, 0xffff, 0xffff, 0xffff, 0xffff, 0xffff, 0xffff, 0xffff, 0xffff, 0xffff, 0xffff, 0xffff,
  0xffff, 0xffff, 0xffff, 0xffff, 0xffff, 0xffff, 0xffff, 0xffff, 0xffff, 0xffff, 0xffff, 0xffff, 0xffff, 0xffff, 0xffff, 0xffff, 0xffff, 0xffff, 0xffff, 0xffff, 0xffff, 0xffff, 0xffff, 0xffff, 0xffff, 0xffff, 0xffff, 0xffff, 0xffff, 0xffff, 0xffff, 0xffff, 0xffff, 0xffff, 0xffff, 0xffff, 0xffff, 0xffff, 0xffff, 0xffff, 0xffff, 0xffff, 0xffff, 0xffff, 0xffff, 0xffff, 0xffff, 0xffff, 0xffff, 0xffff, 0xffff, 0xffff, 0xffff, 0xffff, 0xffff, 0xffff, 0xffff, 0xffff, 0xffff, 0xffff,
  0xffff, 0xffff, 0xffff, 0xffff, 0xffff, 0xffff, 0xffff, 0xffff, 0xffff, 0xffff, 0xffff, 0xffff, 0xffff, 0xffff, 0xffff, 0xffff, 0xffff, 0xffff, 0xffff, 0xffff, 0xffff, 0xffff, 0xffff, 0xffff, 0xffff, 0xffff, 0xffff, 0xffff, 0xffff, 0xffff, 0xffff, 0xffff, 0xffff, 0xffff, 0xffff, 0xffff, 0xffff, 0xffff, 0xffff, 0xffff, 0xffff, 0xffff, 0xffff, 0xffff, 0xffff, 0xffff, 0xffff, 0xffff, 0xffff, 0xffff, 0xffff, 0xffff, 0xffff, 0xffff, 0xffff, 0xffff, 0xffff, 0xffff, 0xffff, 0xffff,
  0xffff, 0xffff, 0xffff, 0xffff, 0xffff, 0xffff, 0xffff, 0xffff, 0xffff, 0xffff, 0xffff, 0xffff, 0xffff, 0xffff, 0xffff, 0xffff, 0xffff, 0xffff, 0xffff, 0xffff, 0xffff, 0xffff, 0xffff, 0xffff, 0xffff, 0xffff, 0xffff, 0xffff, 0xffff, 0xffff, 0xffff, 0xffff, 0xffff, 0xffff, 0xffff, 0xffff, 0xffff, 0xffff, 0xffff, 0xffff, 0xffff, 0xffff, 0xffff, 0xffff, 0xffff, 0xffff, 0xffff, 0xffff, 0xffff, 0xffff, 0xffff, 0xffff, 0xffff, 0xffff, 0xffff, 0xffff, 0xffff, 0xffff, 0xffff, 0xffff,
  0xffff, 0xffff, 0xffff, 0xffff, 0xffff, 0xffff, 0xffff, 0xffff, 0xffff, 0xffff, 0xffff, 0xffff, 0xffff, 0xffff, 0xffff, 0xffff, 0xffff, 0xffff, 0xffff, 0xffff, 0xffff, 0xffff, 0xffff, 0xffff, 0xffff, 0xffff, 0xffff, 0xffff, 0xffff, 0xffff, 0xffff, 0xffff, 0xffff, 0xffff, 0xffff, 0xffff, 0xffff, 0xffff, 0xffff, 0xffff, 0xffff, 0xffff, 0xffff, 0xffff, 0xffff, 0xffff, 0xffff, 0xffff, 0xffff, 0xffff, 0xffff, 0xffff, 0xffff, 0xffff, 0xffff, 0xffff, 0xffff, 0xffff, 0xffff, 0xffff,
  0xffff, 0xffff, 0xffff, 0xffff, 0xffff, 0xffff, 0xffff, 0xffff, 0xffff, 0xffff, 0xffff, 0xffff, 0xffff, 0xffff, 0xffff, 0xffff, 0xffff, 0xffff, 0xffff, 0xffff, 0xffff, 0xffff, 0xffff, 0xffff, 0xffff, 0xffff, 0xffff, 0xffff, 0xffff, 0xffff, 0xffff, 0xffff, 0xffff, 0xffff, 0xffff, 0xffff, 0xffff, 0xffff, 0xffff, 0xffff, 0xffff, 0xffff, 0xffff, 0xffff, 0xffff, 0xffff, 0xffff, 0xffff, 0xffff, 0xffff, 0xffff, 0xffff, 0xffff, 0xffff, 0xffff, 0xffff, 0xffff, 0xffff, 0xffff, 0xffff,
  0xffff, 0xffff, 0xffff, 0xffff, 0xffff, 0xffff, 0xffff, 0xffff, 0xffff, 0xffff, 0xffff, 0xffff, 0xffff, 0xffff, 0xffff, 0xffff, 0xffff, 0xffff, 0xffff, 0xffff, 0xffff, 0xffff, 0xffff, 0xffff, 0xffff, 0xffff, 0xffff, 0xffff, 0xffff, 0xffff, 0xffff, 0xffff, 0xffff, 0xffff, 0xffff, 0xffff, 0xffff, 0xffff, 0xffff, 0xffff, 0xffff, 0xffff, 0xffff, 0xffff, 0xffff, 0xffff, 0xffff, 0xffff, 0xffff, 0xffff, 0xffff, 0xffff, 0xffff, 0xffff, 0xffff, 0xffff, 0xffff, 0xffff, 0xffff, 0xffff,
  0xffff, 0xffff, 0xffff, 0xffff, 0xffff, 0xffff, 0xffff, 0xffff, 0xffff, 0xffff, 0xffff, 0xffff, 0xffff, 0xffff, 0xffff, 0xffff, 0xffff, 0xffff, 0xffff, 0xffff, 0xffff, 0xffff, 0xffff, 0xffff, 0xffff, 0xffff, 0xffff, 0xffff, 0xffff, 0xffff, 0xffff, 0xffff, 0xffff, 0xffff, 0xffff, 0xffff, 0xffff, 0xffff, 0xffff, 0xffff, 0xffff, 0xffff, 0xffff, 0xffff, 0xffff, 0xffff, 0xffff, 0xffff, 0xffff, 0xffff, 0xffff, 0xffff, 0xffff, 0xffff, 0xffff, 0xffff, 0xffff, 0xffff, 0xffff, 0xffff,
  0xffff, 0xffff, 0xffff, 0xffff, 0xffff, 0xffff, 0xffff, 0xffff, 0xffff, 0xffff, 0xffff, 0xffff, 0xffff, 0xffff, 0xffff, 0xffff, 0xffff, 0xffff, 0xffff, 0xffff, 0xffff, 0xffff, 0xffff, 0xffff, 0xffff, 0xffff, 0xffff, 0xffff, 0xffff, 0xffff, 0xffff, 0xffff, 0xffff, 0xffff, 0xffff, 0xffff, 0xffff, 0xffff, 0xffff, 0xffff, 0xffff, 0xffff, 0xffff, 0xffff, 0xffff, 0xffff, 0xffff, 0xffff, 0xffff, 0xffff, 0xffff, 0xffff, 0xffff, 0xffff, 0xffff, 0xffff, 0xffff, 0xffff, 0xffff, 0xffff,
  0xffff, 0xffff, 0xffff, 0xffff, 0xffff, 0xffff, 0xffff, 0xffff, 0xffff, 0xffff, 0xffff, 0xffff, 0xffff, 0xffff, 0xffff, 0xffff, 0xffff, 0xffff, 0xffff, 0xffff, 0xffff, 0xffff, 0xffff, 0xffff, 0xffff, 0xffff, 0xdef7, 0xbde7, 0x7acf, 0x38bf, 0x38b7, 0x38b7, 0x38b7, 0x59c7, 0x9cdf, 0xbdef, 0xdef7, 0xffff, 0xffff, 0xffff, 0xffff, 0xffff, 0xffff, 0xffff, 0xffff, 0xffff, 0xffff, 0xffff, 0xffff, 0xffff, 0xffff, 0xffff, 0xffff, 0xffff, 0xffff, 0xffff, 0xffff, 0xffff, 0xffff, 0xffff,
  0xffff, 0xffff, 0xffff, 0xffff, 0xffff, 0xffff, 0xffff, 0xffff, 0xffff, 0xffff, 0xffff, 0xffff, 0xffff, 0xffff, 0xffff, 0xffff, 0xffff, 0xffff, 0xffff, 0xffff, 0xffff, 0xffff, 0xffff, 0xffff, 0xffff, 0xffff, 0x9cdf, 0x38bf, 0x506e, 0xcc3d, 0xcc3d, 0xcc3d, 0xcc3d, 0x2f66, 0xf6a6, 0x5ac7, 0xbde7, 0xdef7, 0xffff, 0xffff, 0xffff, 0xffff, 0xffff, 0xffff, 0xffff, 0xffff, 0xffff, 0xffff, 0xffff, 0xffff, 0xffff, 0xffff, 0xffff, 0xffff, 0xffff, 0xffff, 0xffff, 0xffff, 0xffff, 0xffff,
  0xffff, 0xffff, 0xffff, 0xffff, 0xffff, 0xffff, 0xffff, 0xffff, 0xffff, 0xffff, 0xffff, 0xffff, 0xffff, 0xffff, 0xffff, 0xffff, 0xffff, 0xffff, 0xffff, 0xffff, 0xffff, 0xffff, 0xffff, 0xffff, 0xdef7, 0xbde7, 0x17af, 0x927e, 0xec45, 0x8925, 0x8925, 0x8925, 0x8925, 0xcc3d, 0x506e, 0xd596, 0x59c7, 0xbde7, 0xffff, 0xffff, 0xffff, 0xffff, 0xffff, 0xffff, 0xffff, 0xffff, 0xffff, 0xffff, 0xffff, 0xffff, 0xffff, 0xffff, 0xffff, 0xffff, 0xffff, 0xffff, 0xffff, 0xffff, 0xffff, 0xffff,
  0xffff, 0xffff, 0xffff, 0xffff, 0xffff, 0xffff, 0xffff, 0xffff, 0xffff, 0xffff, 0xffff, 0xffff, 0xffff, 0xffff, 0xffff, 0xffff, 0xffff, 0xffff, 0xffff, 0xffff, 0xffff, 0xffff, 0xffff, 0xffff, 0x9cdf, 0x39bf, 0x5066, 0xaa2d, 0x8925, 0x8925, 0x8925, 0x8925, 0x8925, 0x8925, 0x8a2d, 0x0e56, 0xd596, 0x7acf, 0xffff, 0xffff, 0xffff, 0xffff, 0xffff, 0xffff, 0xffff, 0xffff, 0xffff, 0xffff, 0xffff, 0xffff, 0xffff, 0xffff, 0xffff, 0xffff, 0xffff, 0xffff, 0xffff, 0xffff, 0xffff, 0xffff,
  0xffff, 0xffff, 0xffff, 0xffff, 0xffff, 0xffff, 0xffff, 0xffff, 0xffff, 0xffff, 0xffff, 0xffff, 0xffff, 0xffff, 0xffff, 0xffff, 0xffff, 0xffff, 0xffff, 0xffff, 0xffff, 0xffff, 0xffff, 0xffff, 0x17af, 0x516e, 0xcc45, 0x8925, 0x8925, 0x8925, 0x8925, 0x8925, 0x8925, 0x8925, 0x8925, 0xcb35, 0x2f5e, 0x17af, 0xffff, 0xffff, 0xffff, 0xffff, 0xffff, 0xffff, 0xffff, 0xffff, 0xffff, 0xffff, 0xffff, 0xffff, 0xffff, 0xffff, 0xffff, 0xffff, 0xffff, 0xffff, 0xffff, 0xffff, 0xffff, 0xffff,
  0xffff, 0xffff, 0xffff, 0xffff, 0xffff, 0xffff, 0xffff, 0xffff, 0xffff, 0xffff, 0xffff, 0xffff, 0xffff, 0xffff, 0xffff, 0xffff, 0xffff, 0xffff, 0xffff, 0xffff, 0xffff, 0xffff, 0xffff, 0xffff, 0x9386, 0x8925, 0x8925, 0x8925, 0x8925, 0x8925, 0x8925, 0x8925, 0x8925, 0x8925, 0x8925, 0x8925, 0x8925, 0xd496, 0xffff, 0xffff, 0xffff, 0xffff, 0xffff, 0xffff, 0xffff, 0xffff, 0xffff, 0xffff, 0xffff, 0xffff, 0xffff, 0xffff, 0xffff, 0xffff, 0xffff, 0xffff, 0xffff, 0xffff, 0xffff, 0xffff,
  0xffff, 0xffff, 0xffff, 0xffff, 0xffff, 0xffff, 0xffff, 0xffff, 0xffff, 0xffff, 0xffff, 0xffff, 0xffff, 0xffff, 0xffff, 0xffff, 0xffff, 0xffff, 0xffff, 0xffff, 0xffff, 0xffff, 0xffff, 0xffff, 0x9386, 0x8925, 0x8925, 0x8925, 0x8925, 0x8925, 0x8925, 0x8925, 0x8925, 0x8925, 0x8925, 0x8925, 0x8925, 0xd496, 0xffff, 0xffff, 0xffff, 0xffff, 0xffff, 0xffff, 0xffff, 0xffff, 0xffff, 0xffff, 0xffff, 0xffff, 0xffff, 0xffff, 0xffff, 0xffff, 0xffff, 0xffff, 0xffff, 0xffff, 0xffff, 0xffff,
  0xffff, 0xffff, 0xffff, 0xffff, 0xffff, 0xffff, 0xffff, 0xffff, 0xffff, 0xffff, 0xffff, 0xffff, 0xffff, 0xffff, 0xffff, 0xffff, 0xffff, 0xffff, 0xffff, 0xffff, 0xffff, 0xffff, 0xffff, 0xffff, 0x937e, 0x8925, 0x8925, 0x8925, 0x8925, 0x8925, 0x8925, 0x8925, 0x8925, 0x8925, 0x8925, 0x8925, 0x8925, 0xd496, 0xffff, 0xffff, 0xffff, 0xffff, 0xffff, 0xffff, 0xffff, 0xffff, 0xffff, 0xffff, 0xffff, 0xffff, 0xffff, 0xffff, 0xffff, 0xffff, 0xffff, 0xffff, 0xffff, 0xffff, 0xffff, 0xffff,
  0xffff, 0xffff, 0xffff, 0xffff, 0xffff, 0xffff, 0xffff, 0xffff, 0xffff, 0xffff, 0xffff, 0xffff, 0xffff, 0xffff, 0xffff, 0xffff, 0xffff, 0xffff, 0xffff, 0xffff, 0xffff, 0xffff, 0xffff, 0xffff, 0x9386, 0x8925, 0x8925, 0x8925, 0x8925, 0x8925, 0x8925, 0x8925, 0x8925, 0x8925, 0x8925, 0x8925, 0x8925, 0xd496, 0xffff, 0xffff, 0xffff, 0xffff, 0xffff, 0xffff, 0xffff, 0xffff, 0xffff, 0xffff, 0xffff, 0xffff, 0xffff, 0xffff, 0xffff, 0xffff, 0xffff, 0xffff, 0xffff, 0xffff, 0xffff, 0xffff,
  0xffff, 0xffff, 0xffff, 0xffff, 0xffff, 0xffff, 0xffff, 0xffff, 0xffff, 0xffff, 0xffff, 0xffff, 0xffff, 0xffff, 0xffff, 0xffff, 0xffff, 0xffff, 0xffff, 0xffff, 0xffff, 0xffff, 0xffff, 0xffff, 0xb48e, 0xab35, 0x8a2d, 0x8925, 0x8925, 0x8925, 0x8925, 0x8925, 0x8925, 0x8925, 0x8925, 0x8925, 0x8925, 0xd496, 0xffff, 0xffff, 0xffff, 0xffff, 0xffff, 0xffff, 0xffff, 0xffff, 0xffff, 0xffff, 0xffff, 0xffff, 0xffff, 0xffff, 0xffff, 0xffff, 0xffff, 0xffff, 0xffff, 0xffff, 0xffff, 0xffff,
  0xffff, 0xffff, 0xffff, 0xffff, 0xffff, 0xffff, 0xffff, 0xffff, 0xffff, 0xffff, 0xffff, 0xffff, 0xffff, 0xffff, 0xffff, 0xffff, 0xffff, 0xffff, 0xffff, 0xffff, 0xffff, 0xffff, 0xffff, 0xffff, 0x38b7, 0x7276, 0xec45, 0x8925, 0x8925, 0x8925, 0x8925, 0x8925, 0x8925, 0x8925, 0x8925, 0x8925, 0x8925, 0xd496, 0xffff, 0xffff, 0xffff, 0xffff, 0xffff, 0xffff, 0xffff, 0xffff, 0xffff, 0xffff, 0xffff, 0xffff, 0xffff, 0xffff, 0xffff, 0xffff, 0xffff, 0xffff, 0xffff, 0xffff, 0xffff, 0xffff,
  0xffff, 0xffff, 0xffff, 0xffff, 0xffff, 0xffff, 0xffff, 0xffff, 0xffff, 0xffff, 0xffff, 0xffff, 0xffff, 0xffff, 0xffff, 0xffff, 0xffff, 0xffff, 0xffff, 0xffff, 0xffff, 0xffff, 0xffff, 0xffff, 0x7acf, 0xf69e, 0x0e56, 0x8925, 0x8925, 0x8925, 0x8925, 0x8925, 0x8925, 0x8925, 0x8925, 0x8925, 0x8925, 0xd496, 0xffff, 0xffff, 0xffff, 0xffff, 0xffff, 0xffff, 0xffff, 0xffff, 0xffff, 0xffff, 0xffff, 0xffff, 0xffff, 0xffff, 0xffff, 0xffff, 0xffff, 0xffff, 0xffff, 0xffff, 0xffff, 0xffff
};
/* USER CODE END PV */

void SystemClock_Config(void);
static void MX_GPIO_Init(void);
static void MX_SPI1_Init(void);

int main(void)
{

  /* MCU Configuration--------------------------------------------------------*/

  /* Reset of all peripherals, Initializes the Flash interface and the Systick. */
  HAL_Init();

  /* Configure the system clock */
  SystemClock_Config();

  /* Initialize all configured peripherals */
  MX_GPIO_Init();
  MX_SPI1_Init();
  /* USER CODE BEGIN 2 */
  ST7789_Init();
  ST7789_Fill_Color(GREEN);
  /* USER CODE END 2 */

  /* Infinite loop */
  while (1)
  {

    /* USER CODE BEGIN 3 */
	  ST7789_DrawImage(50, 50, 60, 60, img0);
	  HAL_Delay(300);
	  ST7789_DrawImage(50, 50, 60, 60, img1);
	  HAL_Delay(300);
	  ST7789_DrawImage(50, 50, 60, 60, img2);
	  HAL_Delay(300);
	  ST7789_DrawImage(50, 50, 60, 60, img1);
	  HAL_Delay(300);

  }
  /* USER CODE END 3 */
}

void SystemClock_Config(void)
{
  RCC_OscInitTypeDef RCC_OscInitStruct = {0};
  RCC_ClkInitTypeDef RCC_ClkInitStruct = {0};

  /** Initializes the RCC Oscillators according to the specified parameters
  * in the RCC_OscInitTypeDef structure.
  */
  RCC_OscInitStruct.OscillatorType = RCC_OSCILLATORTYPE_HSI;
  RCC_OscInitStruct.HSIState = RCC_HSI_ON;
  RCC_OscInitStruct.HSICalibrationValue = RCC_HSICALIBRATION_DEFAULT;
  RCC_OscInitStruct.PLL.PLLState = RCC_PLL_ON;
  RCC_OscInitStruct.PLL.PLLSource = RCC_PLLSOURCE_HSI_DIV2;
  RCC_OscInitStruct.PLL.PLLMUL = RCC_PLL_MUL16;
  if (HAL_RCC_OscConfig(&RCC_OscInitStruct) != HAL_OK)
  {
    Error_Handler();
  }
  /** Initializes the CPU, AHB and APB buses clocks
  */
  RCC_ClkInitStruct.ClockType = RCC_CLOCKTYPE_HCLK|RCC_CLOCKTYPE_SYSCLK
                              |RCC_CLOCKTYPE_PCLK1|RCC_CLOCKTYPE_PCLK2;
  RCC_ClkInitStruct.SYSCLKSource = RCC_SYSCLKSOURCE_PLLCLK;
  RCC_ClkInitStruct.AHBCLKDivider = RCC_SYSCLK_DIV1;
  RCC_ClkInitStruct.APB1CLKDivider = RCC_HCLK_DIV2;
  RCC_ClkInitStruct.APB2CLKDivider = RCC_HCLK_DIV1;

  if (HAL_RCC_ClockConfig(&RCC_ClkInitStruct, FLASH_LATENCY_2) != HAL_OK)
  {
    Error_Handler();
  }
}

static void MX_SPI1_Init(void)
{

  /* SPI1 parameter configuration*/
  hspi1.Instance = SPI1;
  hspi1.Init.Mode = SPI_MODE_MASTER;
  hspi1.Init.Direction = SPI_DIRECTION_2LINES;
  hspi1.Init.DataSize = SPI_DATASIZE_8BIT;
  hspi1.Init.CLKPolarity = SPI_POLARITY_HIGH;
  hspi1.Init.CLKPhase = SPI_PHASE_1EDGE;
  hspi1.Init.NSS = SPI_NSS_SOFT;
  hspi1.Init.BaudRatePrescaler = SPI_BAUDRATEPRESCALER_4;
  hspi1.Init.FirstBit = SPI_FIRSTBIT_MSB;
  hspi1.Init.TIMode = SPI_TIMODE_DISABLE;
  hspi1.Init.CRCCalculation = SPI_CRCCALCULATION_DISABLE;
  hspi1.Init.CRCPolynomial = 10;
  if (HAL_SPI_Init(&hspi1) != HAL_OK)
  {
    Error_Handler();
  }

}

static void MX_GPIO_Init(void)
{
  GPIO_InitTypeDef GPIO_InitStruct = {0};

  /* GPIO Ports Clock Enable */
  __HAL_RCC_GPIOA_CLK_ENABLE();
  __HAL_RCC_GPIOB_CLK_ENABLE();

  /*Configure GPIO pin Output Level */
  HAL_GPIO_WritePin(ST7789_CS_GPIO_Port, ST7789_CS_Pin, GPIO_PIN_RESET);

  /*Configure GPIO pin Output Level */
  HAL_GPIO_WritePin(GPIOB, ST7789_DC_Pin|ST7789_RST_Pin|GPIO_PIN_3|GPIO_PIN_4
                          |GPIO_PIN_5|GPIO_PIN_6, GPIO_PIN_RESET);

  /*Configure GPIO pin : ST7789_CS_Pin */
  GPIO_InitStruct.Pin = ST7789_CS_Pin;
  GPIO_InitStruct.Mode = GPIO_MODE_OUTPUT_PP;
  GPIO_InitStruct.Pull = GPIO_NOPULL;
  GPIO_InitStruct.Speed = GPIO_SPEED_FREQ_LOW;
  HAL_GPIO_Init(ST7789_CS_GPIO_Port, &GPIO_InitStruct);

  /*Configure GPIO pins : ST7789_DC_Pin ST7789_RST_Pin PB3 PB4
                           PB5 PB6 */
  GPIO_InitStruct.Pin = ST7789_DC_Pin|ST7789_RST_Pin|GPIO_PIN_3|GPIO_PIN_4
                          |GPIO_PIN_5|GPIO_PIN_6;
  GPIO_InitStruct.Mode = GPIO_MODE_OUTPUT_PP;
  GPIO_InitStruct.Pull = GPIO_NOPULL;
  GPIO_InitStruct.Speed = GPIO_SPEED_FREQ_LOW;
  HAL_GPIO_Init(GPIOB, &GPIO_InitStruct);

  /*Configure GPIO pins : PA9 PA10 PA11 PA12 */
  GPIO_InitStruct.Pin = GPIO_PIN_9|GPIO_PIN_10|GPIO_PIN_11|GPIO_PIN_12;
  GPIO_InitStruct.Mode = GPIO_MODE_INPUT;
  GPIO_InitStruct.Pull = GPIO_NOPULL;
  HAL_GPIO_Init(GPIOA, &GPIO_InitStruct);

}

void Error_Handler(void)
{
  __disable_irq();
  while (1)
  {
  }
}

/************************ (C) COPYRIGHT STMicroelectronics *****END OF FILE****/
